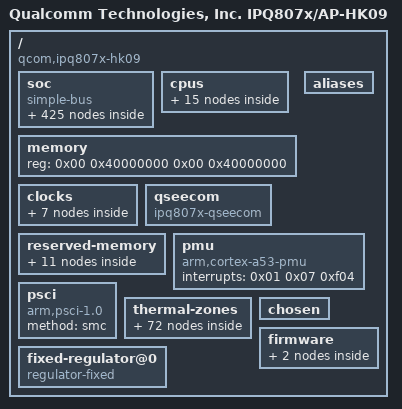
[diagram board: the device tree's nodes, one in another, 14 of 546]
/dts-v1/;

/ {
	qcom,board-id = <0x08 0x00>;
	soc_version_major = <0x2000000>;
	soc_version_minor = <0x00>;
	cpu_type = <0x85010000>;
	flash_type = <0x8000000>;
	boot_version = <0x43524d2d 0x424f4f54 0x2e42462e 0x332e332e 0x312d3030 0x3135360a>;
	#address-cells = <0x02>;
	rpm_version = [43 52 4d 2d 52 50 4d 2e 42 46 2e 32 2e 34 2e 31 2d 30 30 30 38 30 0a];
	tz_version = [43 52 4d 2d 54 5a 2e 42 46 2e 34 2e 30 2e 38 2d 30 30 31 38 39 0a];
	interrupt-parent = <0x01>;
	compatible = "qcom,ipq807x-hk09\0qcom,ipq807x";
	model = "Qualcomm Technologies, Inc. IPQ807x/AP-HK09";
	qcom,pmic-id = <0x00 0x00 0x00 0x00>;
	#size-cells = <0x02>;
	machid = <0x8000108>;
	qcom,msm-id = <0x156 0x00>;

	soc {
		ranges = <0x00 0x00 0x00 0xffffffff>;
		#address-cells = <0x01>;
		compatible = "simple-bus";
		#size-cells = <0x01>;

		ess-switch@3a000000 {
			reset-names = "ppe_rst\0uniphy0_soft_rst\0uniphy0_xpcs_rst\0uniphy1_soft_rst\0uniphy1_xpcs_rst\0uniphy2_soft_rst\0uniphy2_xpcs_rst\0nss_port1_rst\0nss_port2_rst\0nss_port3_rst\0nss_port4_rst\0nss_port5_rst\0nss_port6_rst";
			resets = <0x0b 0x83 0x0b 0x84 0x0b 0x85 0x0b 0x86 0x0b 0x87 0x0b 0x88 0x0b 0x89 0x0b 0x8b 0x0b 0x8c 0x0b 0x8d 0x0b 0x8e 0x0b 0x8f 0x0b 0x90>;
			bm_tick_mode = <0x00>;
			switch_mac_mode = <0x00>;
			switch_inner_bmp = <0x80>;
			switch_mac_mode1 = <0xff>;
			clocks = <0x0b 0xe3 0x0b 0xe4 0x0b 0xb1 0x0b 0xbc 0x0b 0xbd 0x0b 0xc0 0x0b 0xc1 0x0b 0xc4 0x0b 0x92 0x0b 0x93 0x0b 0x94 0x0b 0x95 0x0b 0x96 0x0b 0x97 0x0b 0x86 0x0b 0x85 0x0b 0x8d 0x0b 0x8c 0x0b 0x75 0x0b 0x74 0x0b 0x87 0x0b 0x84 0x0b 0x6d 0x0b 0x77 0x0b 0xd9 0x0b 0x6a 0x0b 0x72 0x0b 0x76 0x0b 0x88 0x0b 0x78 0x0b 0x79 0x0b 0x7a 0x0b 0x7b 0x0b 0x7c 0x0b 0x7d 0x0b 0x7e 0x0b 0x7f 0x0b 0x80 0x0b 0x81 0x0b 0x82 0x0b 0x83 0x0b 0xb2 0x0b 0xb3 0x0b 0xb4 0x0b 0xb5 0x0b 0xb6 0x0b 0xb7 0x0b 0xb8 0x0b 0xb9 0x0b 0xba 0x0b 0xbb 0x0b 0xbe 0x0b 0xbf 0x0b 0xc2 0x0b 0xc3 0x0b 0x0e 0x0b 0x0f>;
			reg = <0x3a000000 0x1000000>;
			switch_access_mode = "local bus";
			switch_mac_mode2 = <0x0d>;
			switch_lan_bmp = <0x3e>;
			switch_wan_bmp = <0x40>;
			compatible = "qcom,ess-switch-ipq807x";
			clock-names = "cmn_ahb_clk\0cmn_sys_clk\0uniphy0_ahb_clk\0uniphy0_sys_clk\0uniphy1_ahb_clk\0uniphy1_sys_clk\0uniphy2_ahb_clk\0uniphy2_sys_clk\0port1_mac_clk\0port2_mac_clk\0port3_mac_clk\0port4_mac_clk\0port5_mac_clk\0port6_mac_clk\0nss_ppe_clk\0nss_ppe_cfg_clk\0nssnoc_ppe_clk\0nssnoc_ppe_cfg_clk\0nss_edma_clk\0nss_edma_cfg_clk\0nss_ppe_ipe_clk\0nss_ppe_btq_clk\0gcc_mdio_ahb_clk\0gcc_nss_noc_clk\0gcc_nssnoc_snoc_clk\0gcc_mem_noc_nss_axi_clk\0gcc_nss_crypto_clk\0gcc_nss_imem_clk\0gcc_nss_ptp_ref_clk\0nss_port1_rx_clk\0nss_port1_tx_clk\0nss_port2_rx_clk\0nss_port2_tx_clk\0nss_port3_rx_clk\0nss_port3_tx_clk\0nss_port4_rx_clk\0nss_port4_tx_clk\0nss_port5_rx_clk\0nss_port5_tx_clk\0nss_port6_rx_clk\0nss_port6_tx_clk\0uniphy0_port1_rx_clk\0uniphy0_port1_tx_clk\0uniphy0_port2_rx_clk\0uniphy0_port2_tx_clk\0uniphy0_port3_rx_clk\0uniphy0_port3_tx_clk\0uniphy0_port4_rx_clk\0uniphy0_port4_tx_clk\0uniphy0_port5_rx_clk\0uniphy0_port5_tx_clk\0uniphy1_port5_rx_clk\0uniphy1_port5_tx_clk\0uniphy2_port6_rx_clk\0uniphy2_port6_tx_clk\0nss_port5_rx_clk_src\0nss_port5_tx_clk_src";
			tm_tick_mode = <0x00>;
			switch_cpu_bmp = <0x01>;

			port_scheduler_resource {

				port@6 {
					l0edrr = <0x80 0x8f>;
					l1cdrr = <0x1c 0x1f>;
					l0sp = <0x38 0x3b>;
					mcast_queue = <0x124 0x127>;
					l0cdrr = <0x80 0x8f>;
					ucast_queue = <0xe0 0xef>;
					l1edrr = <0x1c 0x1f>;
					port_id = <0x06>;
				};

				port@3 {
					l0edrr = <0x50 0x5f>;
					l1cdrr = <0x10 0x13>;
					l0sp = <0x2c 0x2f>;
					mcast_queue = <0x118 0x11b>;
					l0cdrr = <0x50 0x5f>;
					ucast_queue = <0xb0 0xbf>;
					l1edrr = <0x10 0x13>;
					port_id = <0x03>;
				};

				port@0 {
					l0edrr = <0x00 0x2f>;
					l1cdrr = <0x00 0x07>;
					l0sp = <0x00 0x23>;
					mcast_queue = <0x100 0x10f>;
					l0cdrr = <0x00 0x2f>;
					ucast_queue = <0x00 0x8f>;
					l1edrr = <0x00 0x07>;
					port_id = <0x00>;
				};

				port@1 {
					l0edrr = <0x30 0x3f>;
					l1cdrr = <0x08 0x0b>;
					l0sp = <0x24 0x27>;
					mcast_queue = <0x110 0x113>;
					l0cdrr = <0x30 0x3f>;
					ucast_queue = <0x90 0x9f>;
					l1edrr = <0x08 0x0b>;
					port_id = <0x01>;
				};

				port@5 {
					l0edrr = <0x70 0x7f>;
					l1cdrr = <0x18 0x1b>;
					l0sp = <0x34 0x37>;
					mcast_queue = <0x120 0x123>;
					l0cdrr = <0x70 0x7f>;
					ucast_queue = <0xd0 0xdf>;
					l1edrr = <0x18 0x1b>;
					port_id = <0x05>;
				};

				port@4 {
					l0edrr = <0x60 0x6f>;
					l1cdrr = <0x14 0x17>;
					l0sp = <0x30 0x33>;
					mcast_queue = <0x11c 0x11f>;
					l0cdrr = <0x60 0x6f>;
					ucast_queue = <0xc0 0xcf>;
					l1edrr = <0x14 0x17>;
					port_id = <0x04>;
				};

				port@7 {
					l0edrr = <0x90 0x9f>;
					l1cdrr = <0x20 0x23>;
					l0sp = <0x3c 0x3f>;
					mcast_queue = <0x128 0x12b>;
					l0cdrr = <0x90 0x9f>;
					ucast_queue = <0xf0 0xff>;
					l1edrr = <0x20 0x23>;
					port_id = <0x07>;
				};

				port@2 {
					l0edrr = <0x40 0x4f>;
					l1cdrr = <0x0c 0x0f>;
					l0sp = <0x28 0x2b>;
					mcast_queue = <0x114 0x117>;
					l0cdrr = <0x40 0x4f>;
					ucast_queue = <0xa0 0xaf>;
					l1edrr = <0x0c 0x0f>;
					port_id = <0x02>;
				};
			};

			port_scheduler_config {

				port@6 {
					port_id = <0x06>;

					l0scheduler {

						group@0 {
							ucast_loop_pri = <0x10>;
							mcast_queue = <0x124>;
							ucast_queue = <0xe0>;
							cfg = <0x38 0x00 0x80 0x00 0x80>;
							mcast_loop_pri = <0x04>;
						};
					};

					l1scheduler {

						group@1 {
							sp = <0x39>;
							cfg = <0x01 0x1d 0x01 0x1d>;
						};

						group@0 {
							sp = <0x38>;
							cfg = <0x00 0x1c 0x00 0x1c>;
						};
					};
				};

				port@3 {
					port_id = <0x03>;

					l0scheduler {

						group@0 {
							ucast_loop_pri = <0x10>;
							mcast_queue = <0x118>;
							ucast_queue = <0xb0>;
							cfg = <0x2c 0x00 0x50 0x00 0x50>;
							mcast_loop_pri = <0x04>;
						};
					};

					l1scheduler {

						group@1 {
							sp = <0x2d>;
							cfg = <0x01 0x11 0x01 0x11>;
						};

						group@0 {
							sp = <0x2c>;
							cfg = <0x00 0x10 0x00 0x10>;
						};
					};
				};

				port@0 {
					port_id = <0x00>;

					l0scheduler {

						group@3 {
							mcast_queue = <0x103 0x107>;
							ucast_queue = <0x03 0x07 0x0b>;
							cfg = <0x00 0x03 0x03 0x03 0x03>;
						};

						group@1 {
							mcast_queue = <0x101 0x105>;
							ucast_queue = <0x01 0x05 0x09>;
							cfg = <0x00 0x01 0x01 0x01 0x01>;
						};

						group@2 {
							mcast_queue = <0x102 0x106>;
							ucast_queue = <0x02 0x06 0x0a>;
							cfg = <0x00 0x02 0x02 0x02 0x02>;
						};

						group@0 {
							mcast_queue = <0x100 0x104>;
							ucast_queue = <0x00 0x04 0x08>;
							cfg = <0x00 0x00 0x00 0x00 0x00>;
						};
					};

					l1scheduler {

						group@0 {
							sp = <0x00 0x01>;
							cfg = <0x00 0x00 0x00 0x00>;
						};
					};
				};

				port@1 {
					port_id = <0x01>;

					l0scheduler {

						group@0 {
							ucast_loop_pri = <0x10>;
							mcast_queue = <0x110>;
							ucast_queue = <0x90>;
							cfg = <0x24 0x00 0x30 0x00 0x30>;
							mcast_loop_pri = <0x04>;
						};
					};

					l1scheduler {

						group@1 {
							sp = <0x25>;
							cfg = <0x01 0x09 0x01 0x09>;
						};

						group@0 {
							sp = <0x24>;
							cfg = <0x00 0x08 0x00 0x08>;
						};
					};
				};

				port@5 {
					port_id = <0x05>;

					l0scheduler {

						group@0 {
							ucast_loop_pri = <0x10>;
							mcast_queue = <0x120>;
							ucast_queue = <0xd0>;
							cfg = <0x34 0x00 0x70 0x00 0x70>;
							mcast_loop_pri = <0x04>;
						};
					};

					l1scheduler {

						group@1 {
							sp = <0x35>;
							cfg = <0x01 0x19 0x01 0x19>;
						};

						group@0 {
							sp = <0x34>;
							cfg = <0x00 0x18 0x00 0x18>;
						};
					};
				};

				port@4 {
					port_id = <0x04>;

					l0scheduler {

						group@0 {
							ucast_loop_pri = <0x10>;
							mcast_queue = <0x11c>;
							ucast_queue = <0xc0>;
							cfg = <0x30 0x00 0x60 0x00 0x60>;
							mcast_loop_pri = <0x04>;
						};
					};

					l1scheduler {

						group@1 {
							sp = <0x31>;
							cfg = <0x01 0x15 0x01 0x15>;
						};

						group@0 {
							sp = <0x30>;
							cfg = <0x00 0x14 0x00 0x14>;
						};
					};
				};

				port@7 {
					port_id = <0x07>;

					l0scheduler {

						group@0 {
							ucast_loop_pri = <0x10>;
							mcast_queue = <0x128>;
							ucast_queue = <0xf0>;
							cfg = <0x3c 0x00 0x90 0x00 0x90>;
						};
					};

					l1scheduler {

						group@1 {
							sp = <0x3d>;
							cfg = <0x01 0x21 0x01 0x21>;
						};

						group@0 {
							sp = <0x3c>;
							cfg = <0x00 0x20 0x00 0x20>;
						};
					};
				};

				port@2 {
					port_id = <0x02>;

					l0scheduler {

						group@0 {
							ucast_loop_pri = <0x10>;
							mcast_queue = <0x114>;
							ucast_queue = <0xa0>;
							cfg = <0x28 0x00 0x40 0x00 0x40>;
							mcast_loop_pri = <0x04>;
						};
					};

					l1scheduler {

						group@1 {
							sp = <0x29>;
							cfg = <0x01 0x0d 0x01 0x0d>;
						};

						group@0 {
							sp = <0x28>;
							cfg = <0x00 0x0c 0x00 0x0c>;
						};
					};
				};
			};
		};

		syscon@1100000 {
			phandle = <0x17>;
			reg = <0x1100000 0xafff>;
			compatible = "syscon";
			linux,phandle = <0x17>;
		};

		usb3@8A00000 {
			clocks = <0x0b 0xe5 0x0b 0xe6 0x0b 0xc6 0x0b 0xca 0x0b 0xc7 0x0b 0xc8 0x0b 0xc5 0x0b 0xc9>;
			ranges;
			#address-cells = <0x01>;
			assigned-clock-rates = <0x7f27450 0x7f27450 0x1312d00>;
			reg = <0x8af8800 0x100 0x8a00000 0xcd00>;
			status = "ok";
			reg-names = "qscratch_base\0dwc3_base";
			qca,host = <0x01>;
			compatible = "qcom,dwc3";
			clock-names = "snoc_bus_timeout2\0sys_noc_axi\0master\0sleep\0mock_utmi\0cfg_ahb_clk\0aux_clk\0pipe_clk";
			assigned-clocks = <0x0b 0xe6 0x0b 0xc6 0x0b 0xc7>;
			#size-cells = <0x01>;
			qcom,usb-dbm = <0x25>;

			dwc3@8A00000 {
				snps,dis_u2_susphy_quirk;
				dr_mode = "host";
				snps,nominal-elastic-buffer;
				snps,dis_ep_cache_eviction;
				snps,is-utmi-l1-suspend;
				usb-phy = <0x26 0x27>;
				snps,hird-threshold = [00];
				snps,dis_u3_susphy_quirk;
				snps,quirk-ref-clock-period = <0x32>;
				reg = <0x8a00000 0xcd00>;
				tx-fifo-resize;
				interrupts = <0x00 0x8c 0x00>;
				compatible = "snps,dwc3";
				qcom,emulation = <0x01>;
				usb2-susphy-quirk;
				snps,usb3-u1u2-disable;
			};
		};

		dbm@0x8AF8000 {
			qcom,reset-ep-after-lpm-resume;
			phandle = <0x25>;
			reg = <0x8af8000 0x300>;
			compatible = "qcom,usb-dbm-1p5";
			linux,phandle = <0x25>;
		};

		dbgui@6108000 {
			clocks = <0x0b 0xee 0x0b 0xed>;
			reg = <0x6108000 0x1000>;
			qcom,dbgui-addr-offset = <0x30>;
			qcom,dbgui-size = <0x40>;
			reg-names = "dbgui-base";
			coresight-name = "coresight-dbgui";
			compatible = "qcom,coresight-dbgui";
			qcom,dbgui-data-offset = <0x130>;
			clock-names = "core_clk\0core_a_clk";

			port {

				endpoint {
					phandle = <0x43>;
					remote-endpoint = <0x56>;
					linux,phandle = <0x43>;
				};
			};
		};

		clock-controller@b188000 {
			phandle = <0x03>;
			reg = <0xb188000 0x1000>;
			compatible = "qcom,arm-cortex-acc";
			linux,phandle = <0x03>;
		};

		cti@619b000 {
			cpu = <0x52>;
			clocks = <0x0b 0xee 0x0b 0xed>;
			reg = <0x619b000 0x1000>;
			reg-names = "cti-base";
			coresight-name = "coresight-cti-cpu3";
			compatible = "arm,coresight-cti";
			clock-names = "core_clk\0core_a_clk";
		};

		replicator@6026000 {
			clocks = <0x0b 0xee 0x0b 0xed>;
			reg = <0x6026000 0x1000>;
			reg-names = "replicator-base";
			coresight-name = "coresight-replicator";
			compatible = "arm,primecell";
			clock-names = "apb_pclk\0core_a_clk";
			arm,primecell-periphid = <0x3b909>;

			ports {
				#address-cells = <0x01>;
				#size-cells = <0x00>;

				port@0 {
					reg = <0x00>;

					endpoint {
						phandle = <0x36>;
						remote-endpoint = <0x37>;
						linux,phandle = <0x36>;
					};
				};

				port@1 {
					reg = <0x00>;

					endpoint {
						phandle = <0x39>;
						slave-mode;
						remote-endpoint = <0x38>;
						linux,phandle = <0x39>;
					};
				};
			};
		};

		wifi2@f00000 {
			mhi,max-channels = <0x1e>;
			qcom,wlan-ramdump-dynamic = <0x400000>;
			status = "disabled";
			mhi,timeout = <0x2710>;
			qrtr_node_id = <0x20>;
			compatible = "qcom,cnss-qcn9000";
			qca,auto-restart;
		};

		ledc@191E000 {
			qcom,ledc_blink_indices = <0x05 0x06 0x07 0x0e 0x0d 0x01 0x09 0x0a 0x02 0x0b 0x0c 0x03 0x04>;
			qcom,tcsr_ledc_values = <0x320193 0x00 0x00 0x00 0x00 0xffffffff 0x00 0xffffffff 0x7d0820 0x00 0x10482094 0x3ffffe1>;
			reg = <0x191e000 0x20070>;
			qcom,ledc_blink_indices_cnt = <0x0d>;
			status = "disabled";
			reg-names = "ledc_base_addr";
			qcom,ledc_blink_idx_src_pair = <0x03 0x14 0x04 0x15 0x05 0x16>;
			compatible = "qca,ledc";
		};

		dcc@b3000 {
			clocks = <0x0b 0xf3>;
			reg = <0xb3000 0x1000 0xb4000 0x800 0x4a2000 0x08>;
			status = "ok";
			reg-names = "dcc-base\0dcc-ram-base\0gcnt_lo_hi";
			qca,save-reg;
			compatible = "qca,dcc";
			no_xpu_support;
			clock-names = "dcc_clk";
		};

		nss@40000000 {
			qcom,pptp-enabled;
			qcom,vxlan-enabled;
			qcom,igs-enabled;
			qcom,match-enabled;
			qcom,ppe-enabled;
			qcom,num-irq = <0x0a>;
			qcom,tunipip6-enabled;
			qcom,gre-enabled;
			qcom,mirror-enabled;
			qcom,ipv4-reasm-enabled;
			qcom,map-t-enabled;
			qcom,portid-enabled;
			qcom,num-queue = <0x04>;
			qcom,ipv6-reasm-enabled;
			qcom,pppoe-enabled;
			clocks = <0x0b 0x77 0x0b 0x88 0x0b 0x73 0x0b 0x71 0x0b 0x76 0x0b 0x8e 0x0b 0x6a 0x0b 0xd9 0x0b 0x8f 0x0b 0x70 0x0b 0x6f 0x0b 0x8a 0x0b 0x89 0x0b 0x90 0x0b 0x9a 0x0b 0x98 0x0b 0x99 0x0b 0x9b 0x0b 0xda>;
			qcom,gre-redir-mark-enabled;
			qcom,low-frequency = <0x2ca1c800>;
			qcom,mid-frequency = <0x59439000>;
			reg = <0x39000000 0x1000 0x38000000 0x30000 0xb111000 0x1000>;
			qcom,num-pri = <0x04>;
			qcom,gre-redir-enabled;
			qcom,ipv6-enabled;
			qcom,wlanredirect-enabled;
			qcom,l2tpv2-enabled;
			reg-names = "nphys\0vphys\0qgic-phys";
			qcom,load-addr = <0x40000000>;
			qcom,bridge-enabled;
			interrupts = <0x00 0x179 0x01 0x00 0x17a 0x01 0x00 0x17b 0x01 0x00 0x17c 0x01 0x00 0x17d 0x01 0x00 0x17e 0x01 0x00 0x17f 0x01 0x00 0x180 0x01 0x00 0x181 0x01 0x00 0x182 0x01>;
			compatible = "qcom,nss";
			mx-supply = <0x21>;
			clock-names = "nss-noc-clk\0nss-ptp-ref-clk\0nss-csr-clk\0nss-cfg-clk\0nss-imem-clk\0nss-nssnoc-qosgen-ref-clk\0nss-mem-noc-nss-axi-clk\0nss-nssnoc-snoc-clk\0nss-nssnoc-timeout-ref-clk\0nss-ce-axi-clk\0nss-ce-apb-clk\0nss-nssnoc-ce-axi-clk\0nss-nssnoc-ce-apb-clk\0nss-nssnoc-ahb-clk\0nss-core-clk\0nss-ahb-clk\0nss-axi-clk\0nss-mpt-clk\0nss-nc-axi-clk";
			qcom,shaping-enabled;
			qcom,tun6rd-enabled;
			qcom,id = <0x00>;
			npu-supply = <0x20>;
			qcom,vlan-enabled;
			qcom,wlan-dataplane-offload-enabled;
			qcom,ipv4-enabled;
			qcom,max-frequency = <0x64b54000>;
		};

		cti@6018000 {
			phandle = <0x35>;
			clocks = <0x0b 0xee 0x0b 0xed>;
			reg = <0x6018000 0x1000>;
			reg-names = "cti-base";
			coresight-name = "coresight-cti8";
			compatible = "arm,coresight-cti";
			clock-names = "core_clk\0core_a_clk";
			linux,phandle = <0x35>;
		};

		qcom,test@0 {
			status = "disabled";
			compatible = "qcom,testmhi";
		};

		ssphy@78000 {
			reset-names = "usb3_phy_reset\0usb3phy_phy_reset";
			resets = <0x0b 0x29 0x0b 0x2a>;
			qcom,qmp-phy-reg-offset = <0x988 0x98c 0x990 0x994 0x974 0x8d8 0x8dc 0x804 0x800 0x808>;
			phandle = <0x27>;
			clocks = <0x0b 0xc5 0x0b 0xc9>;
			reg = <0x78000 0x45c 0x193f244 0x04 0x8af8800 0x100 0x7e000 0x18>;
			qcom,qmp-phy-init-seq = <0xac 0x14 0x1a 0x00 0x34 0x08 0x08 0x00 0x174 0x30 0x30 0x00 0x3c 0x06 0x06 0x00 0xb4 0x00 0x00 0x00 0xb8 0x08 0x08 0x00 0x194 0x06 0x06 0x3e8 0x19c 0x01 0x01 0x00 0x178 0x00 0x00 0x00 0xd0 0x82 0x82 0x00 0xdc 0x55 0x55 0x00 0xe0 0x55 0x55 0x00 0xe4 0x03 0x03 0x00 0x78 0x0b 0x0b 0x00 0x84 0x16 0x16 0x00 0x90 0x28 0x28 0x00 0x108 0x80 0x80 0x00 0x10c 0x00 0x00 0x00 0x184 0x0a 0x0a 0x00 0x4c 0x15 0x15 0x00 0x50 0x34 0x34 0x00 0x54 0x00 0x00 0x00 0xc8 0x00 0x00 0x00 0x18c 0x00 0x00 0x00 0xcc 0x00 0x00 0x00 0x128 0x00 0x00 0x00 0x0c 0x0a 0x0a 0x00 0x10 0x01 0x01 0x00 0x1c 0x31 0x31 0x00 0x20 0x01 0x01 0x00 0x14 0x00 0x00 0x00 0x18 0x00 0x00 0x00 0x24 0xde 0xde 0x00 0x28 0x07 0x07 0x00 0x48 0x0f 0x0f 0x00 0x70 0x0f 0x0f 0x00 0x100 0x80 0x80 0x00 0x440 0x0b 0x0b 0x00 0x4d8 0x02 0x02 0x00 0x4dc 0x6c 0x6c 0x00 0x4e0 0xbb 0xb8 0x00 0x508 0x77 0x77 0x00 0x50c 0x80 0x80 0x00 0x514 0x03 0x03 0x00 0x51c 0x16 0x16 0x00 0x448 0x75 0x75 0x00 0x454 0x00 0x00 0x00 0x40c 0x0a 0x0a 0x00 0x41c 0x06 0x06 0x00 0x510 0x00 0x00 0x00 0x268 0x45 0x45 0x00 0x2ac 0x12 0x12 0x00 0x294 0x06 0x06 0x00 0x254 0x00 0x00 0x00 0x8c8 0x83 0x83 0x00 0x8c4 0x02 0x02 0x00 0x8cc 0x09 0x09 0x00 0x8d0 0xa2 0xa2 0x00 0x8d4 0x85 0x85 0x00 0x880 0xd1 0xd1 0x00 0x884 0x1f 0x1f 0x00 0x888 0x47 0x47 0x00 0x80c 0x9f 0x9f 0x00 0x824 0x17 0x17 0x00 0x828 0x0f 0x0f 0x00 0x8b8 0x75 0x75 0x00 0x8bc 0x13 0x13 0x00 0x8b0 0x86 0x86 0x00 0x8a0 0x04 0x04 0x00 0x88c 0x44 0x44 0x00 0x870 0xe7 0xe7 0x00 0x874 0x03 0x03 0x00 0x878 0x40 0x40 0x00 0x87c 0x00 0x00 0x00 0x9d8 0x88 0x88 0x00 0xffffffff 0xffffffff 0x00 0x00>;
			status = "ok";
			reg-names = "qmp_phy_base\0vls_clamp_reg\0qscratch_base\0ahb2phy_base";
			compatible = "qcom,usb-ssphy-qmp";
			clock-names = "aux_clk\0pipe_clk";
			linux,phandle = <0x27>;
		};

		dp4 {
			qcom,link-poll = <0x01>;
			qcom,mactype = <0x00>;
			local-mac-address = [00 00 00 00 00 00];
			phy-mode = "sgmii";
			reg = <0x3a001600 0x200>;
			device_type = "network";
			compatible = "qcom,nss-dp";
			qcom,id = <0x04>;
			qcom,phy-mdio-addr = <0x03>;
		};

		csr@6001000 {
			clocks = <0x0b 0xee 0x0b 0xed>;
			qcom,blk-size = <0x01>;
			reg = <0x6001000 0x1000>;
			reg-names = "csr-base";
			coresight-name = "coresight-csr";
			compatible = "qcom,coresight-csr";
			clock-names = "core_clk\0core_a_clk";
		};

		sdcc1ice@7803000 {
			phandle = <0x16>;
			qcom,msm-bus,vectors-KBps = <0x4e 0x200 0x00 0x00 0x4e 0x200 0x3e8 0x00>;
			reg = <0x7803000 0x2000>;
			qcom,bus-vector-names = "MIN\0MAX";
			interrupts = <0x00 0x138 0x00>;
			qcom,instance-type = "sdcc";
			compatible = "qcom,ice";
			linux,phandle = <0x16>;
		};

		qcom,spmi@200f000 {
			qcom,ee = <0x00>;
			#address-cells = <0x02>;
			reg = <0x200f000 0x1000 0x2400000 0x800000 0x2c00000 0x800000 0x3800000 0x200000 0x200a000 0x700>;
			#interrupt-cells = <0x04>;
			interrupt-controller;
			reg-names = "core\0chnls\0obsrvr\0intr\0cnfg";
			interrupt-names = "periph_irq";
			qcom,channel = <0x00>;
			interrupts = <0x00 0xbe 0x00>;
			compatible = "qcom,spmi-pmic-arb";
			#size-cells = <0x00>;
			cell-index = <0x00>;

			pmic@0 {
				#address-cells = <0x01>;
				reg = <0x00 0x00>;
				compatible = "qcom,spmi-pmic";
				#size-cells = <0x00>;

				vadc@3100 {
					#address-cells = <0x01>;
					reg = <0x3100 0x100>;
					interrupts = <0x00 0x31 0x00 0x01>;
					compatible = "qcom,pmp8074-spmi-vadc";
					#io-channel-cells = <0x01>;
					#size-cells = <0x00>;

					die_temp {
						reg = <0x06>;
					};

					pa_therm3 {
						qcom,vadc-thermal-node;
						reg = <0x0f>;
					};

					pa_therm1 {
						qcom,vadc-thermal-node;
						reg = <0x0d>;
					};

					pa_therm2 {
						qcom,vadc-thermal-node;
						reg = <0x0e>;
					};
				};
			};

			pmic@1 {
				#address-cells = <0x01>;
				reg = <0x01 0x00>;
				compatible = "qcom,spmi-pmic";
				#size-cells = <0x00>;

				regulators {
					vdd_ldo11-supply = <0x32>;
					vdd_s4-supply = <0x32>;
					vdd_s3-supply = <0x32>;
					compatible = "qcom,pmd9655-regulators";

					ldo11 {
						regulator-min-microvolt = <0x10d880>;
						regulator-name = "pmd9655_ldo11";
						regulator-max-microvolt = <0x325aa0>;
					};

					s3 {
						regulator-always-on;
						phandle = <0x5b>;
						regulator-boot-on;
						regulator-min-microvolt = <0x90880>;
						regulator-name = "pmd9655_s3";
						regulator-max-microvolt = <0x103c40>;
						linux,phandle = <0x5b>;
					};

					s4 {
						regulator-always-on;
						phandle = <0x5c>;
						regulator-boot-on;
						regulator-min-microvolt = <0xadd40>;
						regulator-name = "pmd9655_s4";
						regulator-max-microvolt = <0xf2300>;
						linux,phandle = <0x5c>;
					};
				};
			};
		};

		cti@6016000 {
			clocks = <0x0b 0xee 0x0b 0xed>;
			reg = <0x6016000 0x1000>;
			reg-names = "cti-base";
			coresight-name = "coresight-cti6";
			compatible = "arm,coresight-cti";
			clock-names = "core_clk\0core_a_clk";
		};

		funnel@6100000 {
			clocks = <0x0b 0xee 0x0b 0xed>;
			reg = <0x6100000 0x1000>;
			reg-names = "funnel-base";
			coresight-name = "coresight-funnel-center";
			compatible = "arm,primecell";
			clock-names = "apb_pclk\0core_a_clk";
			arm,primecell-periphid = <0x3b908>;

			ports {
				#address-cells = <0x01>;
				#size-cells = <0x00>;

				port@0 {
					reg = <0x00>;

					endpoint {
						phandle = <0x3c>;
						remote-endpoint = <0x42>;
						linux,phandle = <0x3c>;
					};
				};

				port@1 {
					reg = <0x02>;

					endpoint {
						phandle = <0x56>;
						slave-mode;
						remote-endpoint = <0x43>;
						linux,phandle = <0x56>;
					};
				};
			};
		};

		qusb@59000 {
			reset-names = "usb2_phy_reset";
			resets = <0x0b 0x30>;
			phandle = <0x28>;
			phy_type = "utmi";
			reg = <0x59000 0x180 0x8cf8800 0x400 0x1841030 0x04>;
			status = "ok";
			reg-names = "qusb_phy_base\0qscratch_base\0ref_clk_addr";
			qcom,qusb-phy-init-seq = <0xf8 0x80 0x83 0x84 0x83 0x88 0xc0 0x8c 0x30 0x08 0x79 0x0c 0x21 0x10 0x14 0x9c 0x80 0x04 0x9f 0x1c>;
			compatible = "qcom,qusb2phy";
			linux,phandle = <0x28>;
		};

		phy@84000 {
			reset-names = "phy\0phy_phy";
			resets = <0x0b 0x4e 0x0b 0x4f>;
			phandle = <0x2b>;
			clocks = <0x0b 0xa4>;
			reg = <0x84000 0x1000>;
			#phy-cells = <0x00>;
			compatible = "qca,pcie-qmp-phy-gen3";
			clock-names = "pipe_clk";
			linux,phandle = <0x2b>;
		};

		pci@10000000 {
			linux,pci-domain = <0x01>;
			reset-names = "pipe\0sleep\0sticky\0axi_m\0axi_s\0ahb\0axi_m_sticky";
			resets = <0x0b 0x7c 0x0b 0x7d 0x0b 0x7e 0x0b 0x7f 0x0b 0x80 0x0b 0x81 0x0b 0x82>;
			clocks = <0x0b 0xea 0x0b 0xa7 0x0b 0xa8 0x0b 0xa5 0x0b 0xa6>;
			phy-names = "pciephy";
			perst-gpio = <0x1d 0x3d 0x01>;
			ranges = <0x81000000 0x00 0x10200000 0x10200000 0x00 0x10000 0x82000000 0x00 0x10220000 0x10220000 0x00 0xfde0000>;
			#address-cells = <0x03>;
			reg = <0x10000000 0xf1d 0x10000f20 0xa8 0x88000 0x2000 0x10100000 0x1000>;
			status = "disabled";
			#interrupt-cells = <0x01>;
			bus-range = <0x00 0xff>;
			interrupt-map = <0x00 0x00 0x00 0x01 0x01 0x00 0x8e 0x04 0x00 0x00 0x00 0x02 0x01 0x00 0x8f 0x04 0x00 0x00 0x00 0x03 0x01 0x00 0x90 0x04 0x00 0x00 0x00 0x04 0x01 0x00 0x91 0x04>;
			reg-names = "dbi\0elbi\0parf\0config";
			interrupt-names = "msi\0msi_0\0msi_1\0msi_2\0msi_3\0msi_4\0msi_5\0msi_6\0msi_7\0msi_8\0msi_9\0msi_10\0msi_11\0msi_12\0msi_13\0msi_14\0msi_15";
			num-lanes = <0x01>;
			device_type = "pci";
			interrupts = <0x00 0x55 0x00 0x00 0x1b0 0x00 0x00 0x1b1 0x00 0x00 0x1b2 0x00 0x00 0x1b3 0x00 0x00 0x1b4 0x00 0x00 0x1b5 0x00 0x00 0x1b6 0x00 0x00 0x1b7 0x00 0x00 0x1b8 0x00 0x00 0x1b9 0x00 0x00 0x1ba 0x00 0x00 0x1bb 0x00 0x00 0x1bc 0x00 0x00 0x1bd 0x00 0x00 0x1be 0x00 0x00 0x1bf 0x00>;
			phys = <0x30>;
			compatible = "qcom,pcie-ipq807x";
			clock-names = "sys_noc\0axi_m\0axi_s\0ahb\0aux";
			interrupt-map-mask = <0x00 0x00 0x00 0x07>;
			qcom,msi-gicm-base = <0x1d0>;
			#size-cells = <0x02>;
			qcom,msi-gicm-addr = <0xb00a040>;

			pcie1_rp {
				reg = <0x00 0x00 0x00 0x00 0x00>;
			};
		};

		cti@6015000 {
			clocks = <0x0b 0xee 0x0b 0xed>;
			reg = <0x6015000 0x1000>;
			reg-names = "cti-base";
			coresight-name = "coresight-cti5";
			compatible = "arm,coresight-cti";
			clock-names = "core_clk\0core_a_clk";
		};

		q6v5_wcss@CD00000 {
			phandle = <0x15>;
			interrupts-extended = <0x01 0x00 0x145 0x01 0x12 0x00 0x00 0x12 0x01 0x00 0x12 0x03 0x00>;
			qca,extended-intc;
			reg = <0xcd00000 0x4040 0x194f000 0x10 0x1952000 0x10 0x4ab000 0x20 0x1818000 0x110 0x1859000 0x10 0x1945000 0x10>;
			qcom,smem-states = <0x13 0x00 0x13 0x01>;
			reg-names = "wcss-base\0tcsr-q6-base\0tcsr-base\0mpm-base\0gcc-wcss-bcr-base\0gcc-wcss-misc-base\0tcsr-global";
			memory-region = <0x10 0x11>;
			interrupt-names = "wdog\0qcom,gpio-err-fatal\0qcom,gpio-err-ready\0qcom,gpio-stop-ack";
			compatible = "qca,q6v5-wcss-rproc-ipq807x";
			qca,auto-restart;
			qca,secure;
			qca,dump-q6-reg;
			qcom,smem-state-names = "shutdown\0stop";
			linux,phandle = <0x15>;
			firmware = "IPQ8074/q6_fw.mdt";
		};

		dp3 {
			qcom,link-poll = <0x01>;
			qcom,mactype = <0x00>;
			local-mac-address = [00 00 00 00 00 00];
			phy-mode = "sgmii";
			reg = <0x3a001400 0x200>;
			device_type = "network";
			compatible = "qcom,nss-dp";
			qcom,id = <0x03>;
			qcom,phy-mdio-addr = <0x02>;
		};

		syscon@1905000 {
			phandle = <0x1b>;
			reg = <0x1905000 0x8000>;
			compatible = "syscon";
			linux,phandle = <0x1b>;
		};

		cti@601b000 {
			clocks = <0x0b 0xee 0x0b 0xed>;
			reg = <0x601b000 0x1000>;
			reg-names = "cti-base";
			coresight-name = "coresight-cti11";
			compatible = "arm,coresight-cti";
			clock-names = "core_clk\0core_a_clk";
		};

		cti@6014000 {
			clocks = <0x0b 0xee 0x0b 0xed>;
			reg = <0x6014000 0x1000>;
			reg-names = "cti-base";
			coresight-name = "coresight-cti4";
			compatible = "arm,coresight-cti";
			clock-names = "core_clk\0core_a_clk";
		};

		syscon@1945000 {
			phandle = <0x1e>;
			reg = <0x1945000 0xe000>;
			compatible = "syscon";
			linux,phandle = <0x1e>;
		};

		cti@619a000 {
			cpu = <0x50>;
			clocks = <0x0b 0xee 0x0b 0xed>;
			reg = <0x619a000 0x1000>;
			reg-names = "cti-base";
			coresight-name = "coresight-cti-cpu2";
			compatible = "arm,coresight-cti";
			clock-names = "core_clk\0core_a_clk";
		};

		i2c@78b6000 {
			dma-names = "rx\0tx";
			clocks = <0x0b 0x54 0x0b 0x57>;
			#address-cells = <0x01>;
			dmas = <0x0e 0x0f 0x0e 0x0e>;
			reg = <0x78b6000 0x600>;
			status = "disabled";
			interrupts = <0x00 0x60 0x04>;
			compatible = "qcom,i2c-qup-v2.2.1";
			clock-names = "iface\0core";
			#size-cells = <0x00>;
			clock-frequency = <0x61a80>;
		};

		cti@610c000 {
			clocks = <0x0b 0xee 0x0b 0xed>;
			reg = <0x610c000 0x1000>;
			reg-names = "cti-base";
			coresight-name = "coresight-cti-rpm-cpu0";
			compatible = "arm,coresight-cti";
			clock-names = "core_clk\0core_a_clk";
		};

		stm@6002000 {
			clocks = <0x0b 0xee 0x0b 0xed>;
			reg = <0x6002000 0x1000 0x9280000 0x180000>;
			reg-names = "stm-base\0stm-data-base";
			coresight-name = "coresight-stm";
			compatible = "arm,primecell";
			clock-names = "apb_pclk\0core_a_clk";
			arm,primecell-periphid = <0x3b962>;

			port {

				endpoint {
					phandle = <0x40>;
					remote-endpoint = <0x55>;
					linux,phandle = <0x40>;
				};
			};
		};

		ess-uniphy@7a00000 {
			reg = <0x7a00000 0x30000>;
			uniphy_access_mode = "local bus";
			compatible = "qcom,ess-uniphy";
		};

		dma@704000 {
			qcom,controlled-remotely = <0x01>;
			phandle = <0x23>;
			clocks = <0x0b 0x67>;
			qcom,ee = <0x01>;
			reg = <0x704000 0x20000>;
			#dma-cells = <0x01>;
			status = "ok";
			interrupts = <0x00 0xcf 0x00>;
			compatible = "qcom,bam-v1.7.0";
			clock-names = "bam_clk";
			linux,phandle = <0x23>;
		};

		qcom_mdss_qpic@7980000 {
			dma-names = "chan";
			clocks = <0x0b 0xac 0x0b 0xab>;
			dmas = <0x24 0x06>;
			reg = <0x7980000 0x24000>;
			status = "disabled";
			interrupts = <0x00 0x97 0x00>;
			compatible = "qcom,mdss_qpic";
			clock-names = "core\0aon";
		};

		usb3@8C00000 {
			clocks = <0x0b 0xe7 0x0b 0xe8 0x0b 0xcc 0x0b 0xd0 0x0b 0xcd 0x0b 0xce 0x0b 0xcb 0x0b 0xcf>;
			ranges;
			#address-cells = <0x01>;
			assigned-clock-rates = <0x7f27450 0x7f27450 0x1312d00>;
			reg = <0x8cf8800 0x100 0x8c00000 0xcd00>;
			status = "ok";
			reg-names = "qscratch_base\0dwc3_base";
			qca,host = <0x01>;
			compatible = "qcom,dwc3";
			clock-names = "snoc_bus_timeout3\0sys_noc_axi\0master\0sleep\0mock_utmi\0cfg_ahb_clk\0aux_clk\0pipe_clk";
			assigned-clocks = <0x0b 0xe8 0x0b 0xcc 0x0b 0xcd>;
			#size-cells = <0x01>;

			dwc3@8C00000 {
				snps,dis_u2_susphy_quirk;
				dr_mode = "host";
				snps,nominal-elastic-buffer;
				snps,dis_ep_cache_eviction;
				snps,is-utmi-l1-suspend;
				usb-phy = <0x28 0x29>;
				snps,hird-threshold = [00];
				snps,dis_u3_susphy_quirk;
				snps,quirk-ref-clock-period = <0x32>;
				reg = <0x8c00000 0xcd00>;
				tx-fifo-resize;
				interrupts = <0x00 0x63 0x00>;
				compatible = "snps,dwc3";
				qcom,emulation = <0x01>;
				usb2-susphy-quirk;
				snps,usb3-u1u2-disable;
			};
		};

		funnel@6120000 {
			clocks = <0x0b 0xee 0x0b 0xed>;
			reg = <0x6120000 0x1000>;
			reg-names = "funnel-base";
			coresight-name = "coresight-funnel-right";
			compatible = "arm,primecell";
			clock-names = "apb_pclk\0core_a_clk";
			arm,primecell-periphid = <0x3b908>;

			ports {
				#address-cells = <0x01>;
				#size-cells = <0x00>;

				port@0 {
					reg = <0x00>;

					endpoint {
						phandle = <0x3d>;
						remote-endpoint = <0x44>;
						linux,phandle = <0x3d>;
					};
				};

				port@1 {
					reg = <0x03>;

					endpoint {
						phandle = <0x47>;
						slave-mode;
						remote-endpoint = <0x45>;
						linux,phandle = <0x47>;
					};
				};
			};
		};

		wifi_platdata {
			status = "ok";
			compatible = "wifi,wifi-platdata";
			wifi,power5v_pa_en_gpio = <0x1d 0x00 0x01>;
		};

		qcom_q6v5_wcss@CD00000 {
			m3_firmware = "IPQ8074/m3_fw.mdt";
			reset-names = "wcss_aon_reset\0wcss_reset\0wcss_q6_reset";
			resets = <0x0b 0x59 0x0b 0x16 0x0b 0x17>;
			phandle = <0x31>;
			interrupts-extended = <0x01 0x00 0x145 0x01 0x12 0x00 0x00 0x12 0x01 0x00 0x12 0x02 0x00 0x12 0x03 0x00>;
			qcom,halt-regs = <0x1e 0xa000 0xd000 0x00>;
			qca,extended-intc;
			reg = <0xcd00000 0x4040 0x4ab000 0x20>;
			qcom,smem-states = <0x13 0x00 0x13 0x01>;
			reg-names = "qdsp6\0rmb";
			memory-region = <0x10 0x11>;
			interrupt-names = "wdog\0fatal\0ready\0handover\0stop-ack";
			compatible = "qcom,ipq8074-wcss-pil";
			qca,auto-restart;
			qcom,smem-state-names = "shutdown\0stop";
			linux,phandle = <0x31>;
			firmware = "IPQ8074/q6_fw.mdt";

			glink-edge {
				global_timer = "\0JP";
				mboxes = <0x1f 0x08>;
				interrupts = <0x00 0x141 0x01>;
				qcom,remote-pid = <0x01>;

				rpm_requests {
					qcom,glink-channels = "IPCRTR";
				};
			};
		};

		cti@601a000 {
			clocks = <0x0b 0xee 0x0b 0xed>;
			reg = <0x601a000 0x1000>;
			reg-names = "cti-base";
			coresight-name = "coresight-cti10";
			compatible = "arm,coresight-cti";
			clock-names = "core_clk\0core_a_clk";
		};

		spi@78b8000 {
			dma-names = "tx\0rx";
			clocks = <0x0b 0x5c 0x0b 0x54>;
			#address-cells = <0x01>;
			dmas = <0x0e 0x12 0x0e 0x13>;
			reg = <0x78b8000 0x600>;
			status = "disabled";
			interrupts = <0x00 0x62 0x00>;
			spi-max-frequency = <0x2faf080>;
			compatible = "qcom,spi-qup-v2.2.1";
			clock-names = "core\0iface";
			#size-cells = <0x00>;
		};

		cti@6011000 {
			clocks = <0x0b 0xee 0x0b 0xed>;
			reg = <0x6011000 0x1000>;
			reg-names = "cti-base";
			coresight-name = "coresight-cti1";
			compatible = "arm,coresight-cti";
			clock-names = "core_clk\0core_a_clk";
		};

		sdhci@7864900 {
			qcom,vdd-io-voltage-level = <0x1b7740 0x2d0370>;
			qcom,bus-width = <0x04>;
			qcom,vdd-io-lpm-sup;
			qcom,msm-bus,vectors-KBps = <0x51 0x200 0x00 0x00 0x51 0x200 0x416 0xc80 0x51 0x200 0xcc3e 0x27100 0x51 0x200 0xff50 0x30d40 0x51 0x200 0x1fe9e 0x61a80 0x51 0x200 0x3fd3e 0xc3500 0x51 0x200 0x3fd3e 0xc3500 0x51 0x200 0x146cc2 0x3e8000>;
			clocks = <0x0b 0xaf 0x0b 0xb0>;
			qcom,vdd-voltage-level = <0x2d0370 0x2d0370>;
			qcom,msm-bus,num-cases = <0x08>;
			reg = <0x7864900 0x500 0x7864000 0x800>;
			qcom,large-address-bus;
			status = "disabled";
			qcom,vdd-io-always-on;
			qcom,vdd-io-current-level = <0xc8 0x55f0>;
			reg-names = "hc_mem\0core_mem";
			qcom,msm-bus,num-paths = <0x01>;
			qcom,max_clk = <0xb71b000>;
			interrupt-names = "hc_irq\0pwr_irq";
			interrupts = <0x00 0x7d 0x00 0x00 0xdd 0x00>;
			qcom,msm-bus,name = "sdhc2";
			qcom,cpu-dma-latency-us = <0x2bd>;
			qcom,vdd-current-level = <0x3a98 0x61a80>;
			qcom,disable-aggressive-pm;
			qcom,dedicated-io = <0x01>;
			compatible = "qcom,sdhci-msm";
			clock-names = "iface_clk\0core_clk";
			qcom,bus-bw-vectors-bps = <0x00 0x61a80 0x1312d00 0x17d7840 0x2faf080 0x5f5e100 0xbebc200 0xffffffff>;
		};

		dp1 {
			qcom,link-poll = <0x01>;
			qcom,mactype = <0x00>;
			local-mac-address = [32 38 38 30 41 32];
			phy-mode = "sgmii";
			reg = <0x3a001000 0x200>;
			device_type = "network";
			compatible = "qcom,nss-dp";
			qcom,id = <0x01>;
			qcom,phy-mdio-addr = <0x00>;
		};

		i2c@78b7000 {
			dma-names = "rx\0tx";
			clocks = <0x0b 0x54 0x0b 0x59>;
			#address-cells = <0x01>;
			dmas = <0x0e 0x11 0x0e 0x10>;
			reg = <0x78b7000 0x600>;
			status = "disabled";
			interrupts = <0x00 0x61 0x04>;
			compatible = "qcom,i2c-qup-v2.2.1";
			clock-names = "iface\0core";
			#size-cells = <0x00>;
			clock-frequency = <0x186a0>;
		};

		etm@619d000 {
			cpu = <0x4e>;
			clocks = <0x0b 0xee 0x0b 0xed>;
			reg = <0x619d000 0x1000>;
			coresight-name = "coresight-etm1";
			compatible = "arm,primecell";
			clock-names = "apb_pclk\0core_a_clk";
			arm,primecell-periphid = <0x3b95d>;

			port {

				endpoint {
					phandle = <0x49>;
					remote-endpoint = <0x4f>;
					linux,phandle = <0x49>;
				};
			};
		};

		gpio_keys {
			pinctrl-0 = <0x5e>;
			pinctrl-names = "default";
			compatible = "gpio-keys";

			button@1 {
				debounce-interval = <0x3c>;
				gpios = <0x1d 0x2f 0x01>;
				linux,code = <0x211>;
				linux,input-type = <0x01>;
				label = "wps";
			};

			button@2 {
				debounce-interval = <0x3c>;
				gpios = <0x1d 0x01 0x01>;
				linux,code = <0x198>;
				linux,input-type = <0x01>;
				label = "reset";
			};
		};

		edma@3ab00000 {
			reset-names = "edma_rst";
			resets = <0x0b 0x8a>;
			qcom,rxdesc-ring-start = <0x0f>;
			qcom,txcmpl-ring-start = <0x07>;
			qcom,txdesc-rings = <0x01>;
			reg = <0x3ab00000 0x76900>;
			qcom,rxfill-rings = <0x01>;
			qcom,txcmpl-rings = <0x01>;
			reg-names = "edma-reg-base";
			interrupts = <0x00 0x159 0x04 0x00 0x161 0x04 0x00 0x169 0x04 0x00 0x158 0x04>;
			compatible = "qcom,edma";
			qcom,rxdesc-rings = <0x01>;
			qcom,txdesc-ring-start = <0x17>;
			qcom,rxfill-ring-start = <0x07>;
		};

		phy@86000 {
			reset-names = "phy\0phy_phy";
			resets = <0x0b 0x4e 0x0b 0x4f>;
			phandle = <0x2a>;
			clocks = <0x0b 0xa4>;
			reg = <0x86000 0x1000>;
			#phy-cells = <0x00>;
			compatible = "qca,pcie-qmp-phy-gen2";
			clock-names = "pipe_clk";
			linux,phandle = <0x2a>;
		};

		tmc@6027000 {
			coresight-ctis = <0x34 0x35>;
			clocks = <0x0b 0xee 0x0b 0xed>;
			reg = <0x6027000 0x1000>;
			reg-names = "tmc-base";
			coresight-name = "coresight-tmc-etf";
			compatible = "arm,primecell";
			clock-names = "apb_pclk\0core_a_clk";
			arm,primecell-periphid = <0x3b961>;
			arm,default-sink;

			ports {
				#address-cells = <0x01>;
				#size-cells = <0x00>;

				port@0 {
					reg = <0x00>;

					endpoint {
						phandle = <0x38>;
						remote-endpoint = <0x39>;
						linux,phandle = <0x38>;
					};
				};

				port@1 {
					reg = <0x00>;

					endpoint {
						phandle = <0x3b>;
						slave-mode;
						remote-endpoint = <0x3a>;
						linux,phandle = <0x3b>;
					};
				};
			};
		};

		dummy-regulator@0 {
			regulator-always-on;
			regulator-boot-on;
			regulator-min-microvolt = <0xcf080>;
			regulator-name = "dummy-reg";
			compatible = "regulator-fixed";
			regulator-max-microvolt = <0xcf080>;
		};

		qca,tzlog {
			qca,hyp-enabled;
			interrupts = <0x00 0xf4 0x01>;
			compatible = "qca,tz64-hv-log";
			qca,tzbsp-diag-buf-size = <0x2000>;
		};

		cti@6017000 {
			clocks = <0x0b 0xee 0x0b 0xed>;
			reg = <0x6017000 0x1000>;
			reg-names = "cti-base";
			coresight-name = "coresight-cti7";
			compatible = "arm,coresight-cti";
			clock-names = "core_clk\0core_a_clk";
		};

		qcom,diag@0 {
			status = "ok";
			compatible = "qcom,diag";
		};

		qpic-nand@79b0000 {
			dma-names = "tx\0rx\0cmd";
			clocks = <0x0b 0xac 0x0b 0xab>;
			#address-cells = <0x01>;
			dmas = <0x24 0x00 0x24 0x01 0x24 0x02>;
			reg = <0x79b0000 0x10000>;
			status = "disabled";
			compatible = "qcom,ebi2-nandc-bam-v1.5.0";
			clock-names = "core\0aon";
			#size-cells = <0x00>;

			nandcs@0 {
				nand-bus-width = <0x08>;
				#address-cells = <0x01>;
				reg = <0x00>;
				nand-ecc-step-size = <0x200>;
				compatible = "qcom,nandcs";
				#size-cells = <0x01>;
				nand-ecc-strength = <0x04>;
			};
		};

		cpr4-ctrl@b018000 {
			qcom,apm-threshold-voltage = <0xcf080>;
			qcom,voltage-step = <0x1f40>;
			vdd-supply = <0x5b>;
			qcom,cpr-down-error-step-limit = <0x01>;
			qcom,apm-ctrl = <0x5a>;
			qcom,cpr-loop-time = <0x4c4b40>;
			qcom,cpr-step-quot-init-min = <0x0c>;
			qcom,cpr-up-error-step-limit = <0x01>;
			reg = <0xb018000 0x4000 0xa4000 0x1000 0x193d008 0x04>;
			qcom,cpr-idle-cycles = <0x0f>;
			reg-names = "cpr_ctrl\0fuse_base\0cpr_tcsr_reg";
			qcom,cpr-count-repeat = <0x0e>;
			qcom,cpr-count-mode = <0x00>;
			interrupt-names = "cpr";
			qcom,cpr-ctrl-name = "apc";
			interrupts = <0x00 0x0f 0x01>;
			compatible = "qcom,cpr4-ipq807x-apss-regulator";
			qcom,cpr-sensor-time = <0x3e8>;
			qcom,cpr-step-quot-init-max = <0x0e>;

			thread@0 {
				qcom,cpr-consecutive-down = <0x00>;
				qcom,cpr-down-threshold = <0x01>;
				qcom,cpr-consecutive-up = <0x00>;
				qcom,cpr-thread-id = <0x00>;
				qcom,cpr-up-threshold = <0x04>;

				regulator {
					qcom,cpr-open-loop-voltage-fuse-adjustment-0 = <0x00 0x00 0x00 0x00 0x00 0x00 0x00 0x00 0x00 0x00 0x00 0x00 0x00 0x00 0x00 0x2ee0 0x00 0x00 0x00 0x00 0x00 0x00 0x00 0x00 0x00 0x00 0x00 0x00 0x00 0x00 0x00 0x00>;
					qcom,cpr-scaled-open-loop-voltage-as-ceiling;
					qcom,cpr-part-types = <0x02>;
					qcom,cpr-speed-bins = <0x01>;
					qcom,cpr-closed-loop-voltage-adjustment-v2-0 = <0x00 0x00 0x00 0x00 0x00 0x00 0x00 0x00 0x00 0x00 0x00 0x00 0x00 0x00 0x00 0x00 0x00 0x00 0x00 0x00 0x00 0x00 0x00 0x00 0x00 0x00 0x00 0x00 0x00 0x00 0x00 0x00>;
					phandle = <0x06>;
					qcom,cpr-voltage-ceiling = <0xcd140 0xdcb40 0xe6780 0xf03c0 0xf2300 0x103c40>;
					qcom,cpr-parts-voltage-v2 = <0xf2300>;
					qcom,cpr-open-loop-voltage-fuse-adjustment-v2-1 = <0x00 0x00 0x00 0x00 0x00 0x1b58 0x8ca0 0xfa0 0x00 0x00 0x00 0x00 0x00 0x00 0x00 0x00 0x00 0x00 0x00 0x00 0x00 0x00 0x00 0x00 0x00 0x00 0x00 0x00 0x00 0x00 0x00 0x00>;
					qcom,cpr-fuse-corners = <0x04>;
					qcom,cpr-closed-loop-voltage-adjustment-v2-1 = <0x00 0x00 0x00 0x00 0x00 0x00 0x4a38 0x00 0x00 0x00 0x00 0x00 0x00 0x00 0x00 0x00 0x00 0x00 0x00 0x00 0x00 0x00 0x00 0x00 0x00 0x00 0x00 0x00 0x00 0x00 0x00 0x00>;
					qcom,cpr-ro-scaling-factor = <0xf82 0x1036 0x00 0x8e8 0x9d8 0x9a6 0x8ca 0x8e8 0x956 0x91a 0x9e2 0x9c4 0x352 0xb54 0x9ce 0x87a 0xf82 0x1036 0x00 0x8e8 0x9d8 0x9a6 0x8ca 0x8e8 0x956 0x91a 0x9e2 0x9c4 0x352 0xb54 0x9ce 0x87a 0xf82 0x1036 0x00 0x8e8 0x9d8 0x9a6 0x8ca 0x8e8 0x956 0x91a 0x9e2 0x9c4 0x352 0xb54 0x9ce 0x87a 0xf82 0x1036 0x00 0x8e8 0x9d8 0x9a6 0x8ca 0x8e8 0x956 0x91a 0x9e2 0x9c4 0x352 0xb54 0x9ce 0x87a>;
					qcom,cpr-corner-fmax-map = <0x01 0x03 0x05 0x06>;
					regulator-min-microvolt = <0x01>;
					qcom,allow-quotient-interpolation;
					qcom,cpr-parts-voltage = <0xffdc0>;
					qcom,cpr-fuse-combos = <0x08>;
					regulator-name = "apc_corner";
					regulator-max-microvolt = <0x06>;
					qcom,allow-voltage-interpolation;
					qcom,cpr-open-loop-voltage-fuse-adjustment-1 = <0x00 0x00 0x00 0x00 0x00 0x00 0x00 0x00 0x00 0x00 0x00 0x00 0x4e20 0x6590 0x00 0x4e20 0x00 0x00 0x00 0x00 0x00 0x00 0x00 0x00 0x00 0x00 0x00 0x00 0x00 0x00 0x00 0x00>;
					qcom,cpr-open-loop-voltage-fuse-adjustment-v2-0 = <0x00 0x00 0x00 0x00 0x00 0x00 0x00 0x00 0x00 0x00 0x00 0x00 0x00 0x00 0x00 0x00 0x00 0x00 0x00 0x00 0x00 0x00 0x00 0x00 0x00 0x00 0x00 0x00 0x00 0x00 0x00 0x00>;
					qcom,cpr-corners = <0x06>;
					qcom,cpr-floor-to-ceiling-max-range = <0x9c40 0x9c40 0x9c40 0x9c40 0x9c40 0x9c40 0x9c40 0x9c40 0x9c40 0x9c40 0x9c40 0x9c40 0x9c40 0x9c40 0x9c40 0x9c40 0x9c40 0x9c40 0x9c40 0x9c40 0x9c40 0x9c40 0x9c40 0x9c40 0x9c40 0x9c40 0x9c40 0x9c40 0x9c40 0x9c40 0x9c40 0x9c40 0x9c40 0x9c40 0x9c40 0x9c40 0x9c40 0x9c40 0x9c40 0x9c40 0x9c40 0x9c40 0x9c40 0x9c40 0x9c40 0x9c40 0x9c40 0x9c40>;
					linux,phandle = <0x06>;
					qcom,cpr-voltage-floor = <0x90880 0x9e340 0xadd40 0xb5a40 0xbf680 0xcf080>;
					qcom,cpr-speed-bin-corners = <0x06>;
					qcom,corner-frequencies = <0x3ca75800 0x5265c000 0x626b5000 0x6ddd0000 0x7270e000 0x839b6800>;
				};
			};
		};

		funnel@6021000 {
			clocks = <0x0b 0xee 0x0b 0xed>;
			reg = <0x6021000 0x1000>;
			reg-names = "funnel-base";
			coresight-name = "coresight-funnel-in0";
			compatible = "arm,primecell";
			clock-names = "apb_pclk\0core_a_clk";
			arm,primecell-periphid = <0x3b908>;

			ports {
				#address-cells = <0x01>;
				#size-cells = <0x00>;

				port@6 {
					reg = <0x00>;

					endpoint {
						phandle = <0x54>;
						slave-mode;
						remote-endpoint = <0x41>;
						linux,phandle = <0x54>;
					};
				};

				port@3 {
					reg = <0x05>;

					endpoint {
						phandle = <0x46>;
						slave-mode;
						remote-endpoint = <0x3e>;
						linux,phandle = <0x46>;
					};
				};

				port@0 {
					reg = <0x00>;

					endpoint {
						phandle = <0x3a>;
						remote-endpoint = <0x3b>;
						linux,phandle = <0x3a>;
					};
				};

				port@1 {
					reg = <0x03>;

					endpoint {
						phandle = <0x42>;
						slave-mode;
						remote-endpoint = <0x3c>;
						linux,phandle = <0x42>;
					};
				};

				port@5 {
					reg = <0x07>;

					endpoint {
						phandle = <0x55>;
						slave-mode;
						remote-endpoint = <0x40>;
						linux,phandle = <0x55>;
					};
				};

				port@4 {
					reg = <0x06>;

					endpoint {
						phandle = <0x57>;
						slave-mode;
						remote-endpoint = <0x3f>;
						linux,phandle = <0x57>;
					};
				};

				port@2 {
					reg = <0x04>;

					endpoint {
						phandle = <0x44>;
						slave-mode;
						remote-endpoint = <0x3d>;
						linux,phandle = <0x44>;
					};
				};
			};
		};

		wifi3@f00000 {
			mhi,max-channels = <0x1e>;
			qcom,wlan-ramdump-dynamic = <0x400000>;
			status = "disabled";
			mhi,timeout = <0x2710>;
			qrtr_node_id = <0x21>;
			compatible = "qcom,cnss-qcn9000";
			qca,auto-restart;
		};

		qcom,sps {
			compatible = "qcom,msm_sps_4k";
			qcom,pipe-attr-ee;
		};

		qcom,gcc@1800000 {
			phandle = <0x0b>;
			#clock-cells = <0x01>;
			reg = <0x1800000 0x80000>;
			compatible = "qcom,gcc-ipq807x";
			#reset-cells = <0x01>;
			linux,phandle = <0x0b>;
		};

		serial@78B3000 {
			pinctrl-0 = <0x0d>;
			tx-watermark = <0x00>;
			clocks = <0x0b 0x65 0x0b 0x54>;
			reg = <0x78b3000 0x200>;
			pinctrl-names = "default";
			status = "ok";
			interrupts = <0x00 0x134 0x00>;
			compatible = "qcom,msm-uartdm-v1.4\0qcom,msm-uartdm";
			clock-names = "core\0iface";
		};

		cti@6013000 {
			clocks = <0x0b 0xee 0x0b 0xed>;
			reg = <0x6013000 0x1000>;
			reg-names = "cti-base";
			coresight-name = "coresight-cti3";
			compatible = "arm,coresight-cti";
			clock-names = "core_clk\0core_a_clk";
		};

		clock-controller@b198000 {
			phandle = <0x07>;
			reg = <0xb198000 0x1000>;
			compatible = "qcom,arm-cortex-acc";
			linux,phandle = <0x07>;
		};

		cti@601d000 {
			clocks = <0x0b 0xee 0x0b 0xed>;
			reg = <0x601d000 0x1000>;
			reg-names = "cti-base";
			coresight-name = "coresight-cti13";
			compatible = "arm,coresight-cti";
			clock-names = "core_clk\0core_a_clk";
		};

		ssphy@58000 {
			reset-names = "usb3_phy_reset\0usb3phy_phy_reset";
			resets = <0x0b 0x2c 0x0b 0x2d>;
			qcom,qmp-phy-reg-offset = <0x988 0x98c 0x990 0x994 0x974 0x8d8 0x8dc 0x804 0x800 0x808>;
			phandle = <0x29>;
			clocks = <0x0b 0xcb 0x0b 0xcf>;
			reg = <0x58000 0x45c 0x8cf8800 0x100 0x5e000 0x18>;
			qcom,qmp-phy-init-seq = <0xac 0x14 0x1a 0x00 0x34 0x08 0x08 0x00 0x174 0x30 0x30 0x00 0x3c 0x06 0x06 0x00 0xb4 0x00 0x00 0x00 0xb8 0x08 0x08 0x00 0x194 0x06 0x06 0x3e8 0x19c 0x01 0x01 0x00 0x178 0x00 0x00 0x00 0xd0 0x82 0x82 0x00 0xdc 0x55 0x55 0x00 0xe0 0x55 0x55 0x00 0xe4 0x03 0x03 0x00 0x78 0x0b 0x0b 0x00 0x84 0x16 0x16 0x00 0x90 0x28 0x28 0x00 0x108 0x80 0x80 0x00 0x10c 0x00 0x00 0x00 0x184 0x0a 0x0a 0x00 0x4c 0x15 0x15 0x00 0x50 0x34 0x34 0x00 0x54 0x00 0x00 0x00 0xc8 0x00 0x00 0x00 0x18c 0x00 0x00 0x00 0xcc 0x00 0x00 0x00 0x128 0x00 0x00 0x00 0x0c 0x0a 0x0a 0x00 0x10 0x01 0x01 0x00 0x1c 0x31 0x31 0x00 0x20 0x01 0x01 0x00 0x14 0x00 0x00 0x00 0x18 0x00 0x00 0x00 0x24 0xde 0xde 0x00 0x28 0x07 0x07 0x00 0x48 0x0f 0x0f 0x00 0x70 0x0f 0x0f 0x00 0x100 0x80 0x80 0x00 0x440 0x0b 0x0b 0x00 0x4d8 0x02 0x02 0x00 0x4dc 0x6c 0x6c 0x00 0x4e0 0xbb 0xb8 0x00 0x508 0x77 0x77 0x00 0x50c 0x80 0x80 0x00 0x514 0x03 0x03 0x00 0x51c 0x16 0x16 0x00 0x448 0x75 0x75 0x00 0x454 0x00 0x00 0x00 0x40c 0x0a 0x0a 0x00 0x41c 0x06 0x06 0x00 0x510 0x00 0x00 0x00 0x268 0x45 0x45 0x00 0x2ac 0x12 0x12 0x00 0x294 0x06 0x06 0x00 0x254 0x00 0x00 0x00 0x8c8 0x83 0x83 0x00 0x8c4 0x02 0x02 0x00 0x8cc 0x09 0x09 0x00 0x8d0 0xa2 0xa2 0x00 0x8d4 0x85 0x85 0x00 0x880 0xd1 0xd1 0x00 0x884 0x1f 0x1f 0x00 0x888 0x47 0x47 0x00 0x80c 0x9f 0x9f 0x00 0x824 0x17 0x17 0x00 0x828 0x0f 0x0f 0x00 0x8b8 0x75 0x75 0x00 0x8bc 0x13 0x13 0x00 0x8b0 0x86 0x86 0x00 0x8a0 0x04 0x04 0x00 0x88c 0x44 0x44 0x00 0x870 0xe7 0xe7 0x00 0x874 0x03 0x03 0x00 0x878 0x40 0x40 0x00 0x87c 0x00 0x00 0x00 0x9d8 0x88 0x88 0x00 0xffffffff 0xffffffff 0x00 0x00>;
			status = "ok";
			reg-names = "qmp_phy_base\0qscratch_base\0ahb2phy_base";
			compatible = "qcom,usb-ssphy-qmp";
			clock-names = "aux_clk\0pipe_clk";
			linux,phandle = <0x29>;
		};

		npu-cpr {
			qcom,voltage-step = <0x1f40>;
			vdd-supply = <0x5c>;
			reg = <0xa4000 0x1000 0x193d008 0x04>;
			reg-names = "fuse_base\0cpr_tcsr_reg";
			qcom,cpr-ctrl-name = "npu";
			compatible = "qcom,cpr3-ipq807x-npu-regulator";

			thread@0 {
				qcom,cpr-consecutive-down = <0x02>;
				qcom,cpr-down-threshold = <0x01>;
				qcom,cpr-consecutive-up = <0x00>;
				qcom,cpr-thread-id = <0x00>;
				qcom,cpr-up-threshold = <0x02>;

				regulator {
					qcom,cpr-cold-temp-threshold-v2 = <0x1e>;
					qcom,cpr-open-loop-voltage-fuse-adjustment-0 = <0x9c40 0x9c40>;
					qcom,cpr-part-types = <0x02>;
					qcom,cpr-speed-bins = <0x01>;
					phandle = <0x20>;
					qcom,cpr-voltage-ceiling = <0xdea80 0xf2300>;
					qcom,cpr-cold-temp-voltage-adjustment-v2-1 = <0x88b8 0x6978>;
					qcom,cpr-parts-voltage-v2 = <0xcb201>;
					qcom,cpr-open-loop-voltage-fuse-adjustment-v2-1 = <0x9c40 0x9c40>;
					qcom,cpr-fuse-corners = <0x02>;
					qcom,cpr-cold-temp-voltage-adjustment-v2-0 = <0x00 0x00>;
					qcom,cpr-corner-fmax-map = <0x01 0x02>;
					regulator-min-microvolt = <0x01>;
					qcom,cpr-parts-voltage = <0xec540>;
					qcom,cpr-fuse-combos = <0x01>;
					regulator-name = "npu_corner";
					regulator-max-microvolt = <0x03>;
					qcom,allow-voltage-interpolation;
					qcom,cpr-open-loop-voltage-fuse-adjustment-1 = <0x5dc0 0x5dc0>;
					qcom,cpr-open-loop-voltage-fuse-adjustment-v2-0 = <0x9c40 0x9c40>;
					qcom,cpr-corners = <0x02>;
					linux,phandle = <0x20>;
					qcom,cpr-voltage-floor = <0xb7980 0xc15c0>;
					qcom,cpr-speed-bin-corners = <0x02>;
					qcom,corner-frequencies = <0x59439000 0x64b54000>;
				};
			};
		};

		mailbox@b111000 {
			#mbox-cells = <0x01>;
			phandle = <0x1f>;
			compatible = "qcom,msm8996-apcs-hmss-global";
			qcom,ipc = <0x18 0x08 0x08>;
			linux,phandle = <0x1f>;
		};

		pci@20000000 {
			linux,pci-domain = <0x00>;
			reset-names = "pipe\0sleep\0sticky\0axi_m\0axi_s\0ahb\0axi_m_sticky\0axi_s_sticky";
			resets = <0x0b 0x75 0x0b 0x76 0x0b 0x77 0x0b 0x78 0x0b 0x79 0x0b 0x7a 0x0b 0x7b 0x0b 0x7b>;
			pinctrl-0 = <0x2c 0x2d>;
			e911-gpio = <0x1d 0x21 0x00>;
			clocks = <0x0b 0xe9 0x0b 0xa2 0x0b 0xa3 0x0b 0xa0 0x0b 0xa1 0x0b 0xf5 0x0b 0xf6>;
			phy-names = "pciephy-gen2\0pciephy-gen3";
			perst-gpio = <0x1d 0x3a 0x01>;
			interrupts-extended = <0x01 0x00 0x34 0x00 0x01 0x00 0x1a0 0x00 0x01 0x00 0x1a1 0x00 0x01 0x00 0x1a2 0x00 0x01 0x00 0x1a3 0x00 0x01 0x00 0x1a4 0x00 0x01 0x00 0x1a5 0x00 0x01 0x00 0x1a6 0x00 0x01 0x00 0x1a7 0x00 0x01 0x00 0x1a8 0x00 0x01 0x00 0x1a9 0x00 0x01 0x00 0x1aa 0x00 0x01 0x00 0x1ab 0x00 0x01 0x00 0x1ac 0x00 0x01 0x00 0x1ad 0x00 0x01 0x00 0x1ae 0x00 0x01 0x00 0x1af 0x00 0x1d 0x3b 0x00 0x1d 0x21 0x00>;
			ranges = <0x81000000 0x00 0x20200000 0x20200000 0x00 0x10000 0x82000000 0x00 0x20220000 0x20220000 0x00 0xfde0000>;
			#address-cells = <0x03>;
			use_delay = <0x00>;
			reg = <0x20000000 0xf1d 0x20000f20 0xa8 0x20001000 0x1000 0x80000 0x2000 0x20100000 0x1000>;
			pinctrl-names = "default";
			status = "ok";
			#interrupt-cells = <0x01>;
			bus-range = <0x00 0xff>;
			interrupt-map = <0x00 0x00 0x00 0x01 0x01 0x00 0x4b 0x04 0x00 0x00 0x00 0x02 0x01 0x00 0x4e 0x04 0x00 0x00 0x00 0x03 0x01 0x00 0x4f 0x04 0x00 0x00 0x00 0x04 0x01 0x00 0x53 0x04>;
			reg-names = "dbi\0elbi\0dm_iatu\0parf\0config";
			interrupt-names = "msi\0msi_0\0msi_1\0msi_2\0msi_3\0msi_4\0msi_5\0msi_6\0msi_7\0msi_8\0msi_9\0msi_10\0msi_11\0msi_12\0msi_13\0msi_14\0msi_15\0wake_gpio\0mdm2ap_e911";
			num-lanes = <0x01>;
			device_type = "pci";
			interrupts = <0x00 0x34 0x00 0x00 0x1a0 0x00 0x00 0x1a1 0x00 0x00 0x1a2 0x00 0x00 0x1a3 0x00 0x00 0x1a4 0x00 0x00 0x1a5 0x00 0x00 0x1a6 0x00 0x00 0x1a7 0x00 0x00 0x1a8 0x00 0x00 0x1a9 0x00 0x00 0x1aa 0x00 0x00 0x1ab 0x00 0x00 0x1ac 0x00 0x00 0x1ad 0x00 0x00 0x1ae 0x00 0x00 0x1af 0x00>;
			phys = <0x2a 0x2b>;
			compatible = "qcom,pcie-ipq807x";
			clock-names = "sys_noc\0axi_m\0axi_s\0ahb\0aux\0axi_bridge\0rchng";
			interrupt-map-mask = <0x00 0x00 0x00 0x07>;
			qcom,msi-gicm-base = <0x1c0>;
			#size-cells = <0x02>;
			link_retries_count = <0x64>;
			qcom,msi-gicm-addr = <0xb00a040>;

			pcie0_rp {
				#address-cells = <0x05>;
				reg = <0x00 0x00 0x00 0x00 0x00>;
				status = "ok";
				#size-cells = <0x00>;

				aliases {
					mhi-netdev0 = "/soc/pci@20000000/pcie0_rp/qcom,mhi@0/mhi_devices/mhi_rmnet@0";
					mhi_netdev2 = "/soc/pci@20000000/pcie0_rp/qcom,mhi@0/mhi_devices/mhi_rmnet@2";
				};

				qcom,mhi@0 {
					mhi,max-channels = <0x6e>;
					pinctrl-0 = <0x2e>;
					ap2mdm = <0x1a>;
					reg = <0x00 0x00 0x00 0x00 0x00>;
					pinctrl-names = "default";
					qcom,iommu-dma = "disabled";
					mhi,timeout = <0xea60>;
					mhi,ssr-negotiate;
					mdm2ap = <0x19>;

					mhi_devices {
						#address-cells = <0x01>;
						#size-cells = <0x00>;

						mhi_qrtr {
							qcom,net-id = <0x03>;
							mhi,chan = "IPCR";
						};

						mhi_rmnet@1 {
							mhi,chan = "IP_HW0_RSC";
							reg = <0x01>;
							mhi,rsc-parent = <0x2f>;
							mhi,mru = <0x8000>;
						};

						mhi_rmnet@2 {
							mhi,chan = "IP_SW0";
							reg = <0x02>;
							mhi,disable-chain-skb;
							mhi,interface-name = "rmnet_mhi_sw";
							mhi,mru = <0x4000>;
						};

						mhi_rmnet@0 {
							phandle = <0x2f>;
							mhi,chan = "IP_HW0";
							reg = <0x00>;
							mhi,chain-skb;
							linux,phandle = <0x2f>;
							mhi,interface-name = "rmnet_mhi";
							mhi,mru = <0x4000>;
						};
					};

					mhi_channels {
						#address-cells = <0x01>;
						#size-cells = <0x00>;

						mhi_chan@5 {
							mhi,chan-dir = <0x02>;
							mhi,num-elements = <0x40>;
							mhi,event-ring = <0x03>;
							reg = <0x05>;
							mhi,data-type = <0x00>;
							mhi,doorbell-mode = <0x02>;
							label = "DIAG";
							mhi,ee = <0x04>;
						};

						mhi_chan@18 {
							mhi,chan-dir = <0x01>;
							mhi,num-elements = <0x40>;
							mhi,event-ring = <0x01>;
							reg = <0x12>;
							mhi,data-type = <0x00>;
							mhi,doorbell-mode = <0x02>;
							label = "IP_CTRL";
							mhi,ee = <0x04>;
						};

						mhi_chan@47 {
							mhi,chan-dir = <0x02>;
							mhi,num-elements = <0x200>;
							mhi,event-ring = <0x05>;
							reg = <0x2f>;
							mhi,data-type = <0x04>;
							mhi,doorbell-mode = <0x02>;
							label = "IP_SW0";
							mhi,ee = <0x04>;
						};

						mhi_chan@21 {
							mhi,chan-dir = <0x02>;
							mhi,num-elements = <0x40>;
							mhi,event-ring = <0x02>;
							mhi,auto-queue;
							reg = <0x15>;
							mhi,data-type = <0x00>;
							mhi,auto-start;
							mhi,doorbell-mode = <0x02>;
							label = "IPCR";
							mhi,ee = <0x04>;
						};

						mhi_chan@46 {
							mhi,chan-dir = <0x01>;
							mhi,num-elements = <0x200>;
							mhi,event-ring = <0x04>;
							reg = <0x2e>;
							mhi,data-type = <0x01>;
							mhi,doorbell-mode = <0x02>;
							label = "IP_SW0";
							mhi,ee = <0x04>;
						};

						mhi_chan@106 {
							mhi,chan-dir = <0x02>;
							mhi,num-elements = <0x80>;
							mhi,event-ring = <0x0b>;
							reg = <0x6a>;
							mhi,data-type = <0x00>;
							mhi,doorbell-mode = <0x02>;
							label = "RMNET_CTL";
							mhi,ee = <0x04>;
						};

						mhi_chan@20 {
							mhi,chan-dir = <0x01>;
							mhi,num-elements = <0x40>;
							mhi,event-ring = <0x02>;
							reg = <0x14>;
							mhi,data-type = <0x01>;
							mhi,auto-start;
							mhi,doorbell-mode = <0x02>;
							label = "IPCR";
							mhi,ee = <0x04>;
						};

						mhi_chan@105 {
							mhi,chan-dir = <0x01>;
							mhi,num-elements = <0x80>;
							mhi,event-ring = <0x0a>;
							reg = <0x69>;
							mhi,data-type = <0x01>;
							mhi,doorbell-mode = <0x02>;
							label = "RMNET_CTL";
							mhi,ee = <0x04>;
						};

						mhi_chan@16 {
							mhi,chan-dir = <0x01>;
							mhi,num-elements = <0x40>;
							mhi,event-ring = <0x03>;
							reg = <0x10>;
							mhi,data-type = <0x00>;
							mhi,doorbell-mode = <0x02>;
							label = "QMI1";
							mhi,ee = <0x04>;
						};

						mhi_chan@0 {
							mhi,chan-dir = <0x01>;
							mhi,num-elements = <0x40>;
							mhi,event-ring = <0x02>;
							reg = <0x00>;
							mhi,data-type = <0x00>;
							mhi,doorbell-mode = <0x02>;
							label = "LOOPBACK";
							mhi,ee = <0x04>;
						};

						mhi_chan@19 {
							mhi,chan-dir = <0x02>;
							mhi,num-elements = <0x40>;
							mhi,event-ring = <0x01>;
							mhi,auto-queue;
							reg = <0x13>;
							mhi,data-type = <0x00>;
							mhi,doorbell-mode = <0x02>;
							label = "IP_CTRL";
							mhi,ee = <0x04>;
						};

						mhi_chan@102 {
							mhi,chan-dir = <0x02>;
							mhi,event-ring = <0x08>;
							mhi,offload-chan;
							reg = <0x66>;
							mhi,data-type = <0x03>;
							label = "IP_HW_ADPL";
							mhi,ee = <0x04>;
							mhi,lpm-notify;
						};

						mhi_chan@100 {
							mhi,chan-dir = <0x01>;
							mhi,num-elements = <0x200>;
							mhi,event-ring = <0x06>;
							mhi,db-mode-switch;
							reg = <0x64>;
							mhi,data-type = <0x01>;
							mhi,doorbell-mode = <0x03>;
							label = "IP_HW0";
							mhi,ee = <0x04>;
						};

						mhi_chan@14 {
							mhi,chan-dir = <0x01>;
							mhi,num-elements = <0x40>;
							mhi,event-ring = <0x01>;
							reg = <0x0e>;
							mhi,data-type = <0x00>;
							mhi,doorbell-mode = <0x02>;
							label = "QMI0";
							mhi,ee = <0x04>;
						};

						mhi_chan@4 {
							mhi,chan-dir = <0x01>;
							mhi,num-elements = <0x40>;
							mhi,event-ring = <0x01>;
							reg = <0x04>;
							mhi,data-type = <0x00>;
							mhi,doorbell-mode = <0x02>;
							label = "DIAG";
							mhi,ee = <0x04>;
						};

						mhi_chan@17 {
							mhi,chan-dir = <0x02>;
							mhi,num-elements = <0x40>;
							mhi,event-ring = <0x03>;
							reg = <0x11>;
							mhi,data-type = <0x00>;
							mhi,doorbell-mode = <0x02>;
							label = "QMI1";
							mhi,ee = <0x04>;
						};

						mhi_chan@1 {
							mhi,chan-dir = <0x02>;
							mhi,num-elements = <0x40>;
							mhi,event-ring = <0x02>;
							reg = <0x01>;
							mhi,data-type = <0x00>;
							mhi,doorbell-mode = <0x02>;
							label = "LOOPBACK";
							mhi,ee = <0x04>;
						};

						mhi_chan@15 {
							mhi,chan-dir = <0x02>;
							mhi,num-elements = <0x40>;
							mhi,event-ring = <0x02>;
							reg = <0x0f>;
							mhi,data-type = <0x00>;
							mhi,doorbell-mode = <0x02>;
							label = "QMI0";
							mhi,ee = <0x04>;
						};

						mhi_chan@101 {
							mhi,chan-dir = <0x02>;
							mhi,num-elements = <0x200>;
							mhi,event-ring = <0x07>;
							reg = <0x65>;
							mhi,data-type = <0x04>;
							mhi,doorbell-mode = <0x03>;
							label = "IP_HW0";
							mhi,ee = <0x04>;
						};
					};

					mhi_events {
						#address-cells = <0x01>;
						#size-cells = <0x00>;

						mhi_event@6 {
							mhi,num-elements = <0x400>;
							mhi,chan = <0x64>;
							mhi,priority = <0x01>;
							mhi,brstmode = <0x03>;
							mhi,msi = <0x05>;
							mhi,intmod = <0x05>;
							mhi,hw-ev;
						};

						mhi_event@5 {
							mhi,num-elements = <0x400>;
							mhi,chan = <0x2f>;
							mhi,priority = <0x01>;
							mhi,client-manage;
							mhi,brstmode = <0x02>;
							mhi,msi = <0x06>;
							mhi,intmod = <0x05>;
						};

						mhi_event@4 {
							mhi,num-elements = <0x400>;
							mhi,chan = <0x2e>;
							mhi,priority = <0x01>;
							mhi,brstmode = <0x02>;
							mhi,msi = <0x05>;
							mhi,intmod = <0x05>;
						};

						mhi_event@2 {
							mhi,num-elements = <0x100>;
							mhi,priority = <0x01>;
							mhi,brstmode = <0x02>;
							mhi,msi = <0x03>;
							mhi,intmod = <0x01>;
						};

						mhi_event@1 {
							mhi,num-elements = <0x100>;
							mhi,priority = <0x01>;
							mhi,brstmode = <0x02>;
							mhi,msi = <0x02>;
							mhi,intmod = <0x01>;
						};

						mhi_event@12 {
							mhi,offload;
							mhi,num-elements = <0x00>;
							mhi,chan = <0x6b>;
							mhi,priority = <0x01>;
							mhi,client-manage;
							mhi,brstmode = <0x03>;
							mhi,msi = <0x00>;
							mhi,intmod = <0x00>;
							mhi,hw-ev;
						};

						mhi_event@13 {
							mhi,offload;
							mhi,num-elements = <0x00>;
							mhi,chan = <0x6c>;
							mhi,priority = <0x01>;
							mhi,client-manage;
							mhi,brstmode = <0x03>;
							mhi,msi = <0x00>;
							mhi,intmod = <0x00>;
							mhi,hw-ev;
						};

						mhi_event@10 {
							mhi,num-elements = <0x400>;
							mhi,chan = <0x69>;
							mhi,priority = <0x00>;
							mhi,brstmode = <0x02>;
							mhi,msi = <0x08>;
							mhi,intmod = <0x01>;
							mhi,hw-ev;
						};

						mhi_event@7 {
							mhi,num-elements = <0x400>;
							mhi,chan = <0x65>;
							mhi,priority = <0x01>;
							mhi,client-manage;
							mhi,brstmode = <0x03>;
							mhi,msi = <0x06>;
							mhi,intmod = <0x05>;
							mhi,hw-ev;
						};

						mhi_event@8 {
							mhi,offload;
							mhi,num-elements = <0x00>;
							mhi,chan = <0x66>;
							mhi,priority = <0x01>;
							mhi,client-manage;
							mhi,brstmode = <0x03>;
							mhi,msi = <0x00>;
							mhi,intmod = <0x00>;
							mhi,hw-ev;
						};

						mhi_event@3 {
							mhi,num-elements = <0x100>;
							mhi,priority = <0x01>;
							mhi,brstmode = <0x02>;
							mhi,msi = <0x04>;
							mhi,intmod = <0x01>;
						};

						mhi_event@0 {
							mhi,num-elements = <0x20>;
							mhi,priority = <0x01>;
							reg = <0x00>;
							mhi,data-type = <0x01>;
							mhi,brstmode = <0x02>;
							mhi,msi = <0x01>;
							mhi,intmod = <0x01>;
						};

						mhi_event@9 {
							mhi,num-elements = <0x400>;
							mhi,chan = <0x67>;
							mhi,priority = <0x01>;
							mhi,brstmode = <0x02>;
							mhi,msi = <0x07>;
							mhi,intmod = <0x05>;
							mhi,hw-ev;
						};

						mhi_event@11 {
							mhi,num-elements = <0x400>;
							mhi,chan = <0x6a>;
							mhi,priority = <0x00>;
							mhi,brstmode = <0x02>;
							mhi,msi = <0x09>;
							mhi,intmod = <0x00>;
							mhi,hw-ev;
						};
					};
				};
			};
		};

		clock-controller@b1a8000 {
			phandle = <0x09>;
			reg = <0xb1a8000 0x1000>;
			compatible = "qcom,arm-cortex-acc";
			linux,phandle = <0x09>;
		};

		mdio@90000 {
			pinctrl-0 = <0x1c>;
			phy-reset-gpio = <0x1d 0x25 0x00>;
			#address-cells = <0x01>;
			reg = <0x90000 0x64>;
			pinctrl-names = "default";
			compatible = "qcom,ipq40xx-mdio";
			#size-cells = <0x01>;

			ethernet-phy@1 {
				reg = <0x01>;
			};

			ethernet-phy@2 {
				reg = <0x02>;
			};

			ethernet-phy@3 {
				reg = <0x03>;
			};

			ethernet-phy@4 {
				reg = <0x04>;
			};

			ethernet-phy@0 {
				reg = <0x00>;
			};

			ethernet-phy@5 {
				reg = <0x07>;
				compatible = "ethernet-phy-ieee802.3-c45";
			};
		};

		spi@78b5000 {
			pinctrl-0 = <0x0f>;
			dma-names = "tx\0rx";
			clocks = <0x0b 0x56 0x0b 0x54>;
			#address-cells = <0x01>;
			dmas = <0x0e 0x0c 0x0e 0x0d>;
			reg = <0x78b5000 0x600>;
			cs-select = <0x00>;
			pinctrl-names = "default";
			status = "ok";
			interrupts = <0x00 0x5f 0x00>;
			spi-max-frequency = <0x2faf080>;
			compatible = "qcom,spi-qup-v2.2.1";
			clock-names = "core\0iface";
			#size-cells = <0x00>;

			m25p80@0 {
				density = <0x1000000>;
				sector-size = <0x10000>;
				#address-cells = <0x01>;
				reg = <0x00>;
				use-default-sizes;
				spi-max-frequency = <0x2faf080>;
				compatible = "n25q128a11";
				linux,modalias = "m25p80\0n25q128a11";
				#size-cells = <0x01>;

				partition@3b0000 {
					reg = <0x3b0000 0x10000>;
					label = "0:DEVCFG";
				};

				partition@0 {
					reg = <0x00 0x50000>;
					label = "0:SBL1";
				};

				partition@460000 {
					reg = <0x460000 0x10000>;
					label = "0:CDT_1";
				};

				partition@80000 {
					reg = <0x80000 0x20000>;
					label = "0:BOOTCONFIG1";
				};

				partition@470000 {
					reg = <0x470000 0x10000>;
					label = "0:CDT";
				};

				partition@610000 {
					reg = <0x610000 0x80000>;
					label = "0:ETHPHYFW";
				};

				partition@5d0000 {
					reg = <0x5d0000 0x40000>;
					label = "0:ART";
				};

				partition@480000 {
					reg = <0x480000 0x10000>;
					label = "0:APPSBLENV";
				};

				partition@220000 {
					reg = <0x220000 0x180000>;
					label = "0:QSEE";
				};

				partition@3a0000 {
					reg = <0x3a0000 0x10000>;
					label = "0:DEVCFG_1";
				};

				partition@490000 {
					reg = <0x490000 0xa0000>;
					label = "0:APPSBL_1";
				};

				partition@3c0000 {
					reg = <0x3c0000 0x10000>;
					label = "0:APDP";
				};

				partition@3e0000 {
					reg = <0x3e0000 0x40000>;
					label = "0:RPM_1";
				};

				partition@60000 {
					reg = <0x60000 0x20000>;
					label = "0:BOOTCONFIG";
				};

				partition@420000 {
					reg = <0x420000 0x40000>;
					label = "0:RPM";
				};

				partition@3d0000 {
					reg = <0x3d0000 0x10000>;
					label = "0:APDP_1";
				};

				partition@530000 {
					reg = <0x530000 0xa0000>;
					label = "0:APPSBL";
				};

				partition@50000 {
					reg = <0x50000 0x10000>;
					label = "0:MIBIB";
				};

				partition@a0000 {
					reg = <0xa0000 0x180000>;
					label = "0:QSEE_1";
				};
			};
		};

		pinctrl@1000000 {
			pinctrl-0 = <0x0c>;
			phandle = <0x1d>;
			gpio-controller;
			reg = <0x1000000 0x300000>;
			pinctrl-names = "default";
			#interrupt-cells = <0x02>;
			interrupt-controller;
			#gpio-cells = <0x02>;
			interrupts = <0x00 0xd0 0x00>;
			compatible = "qcom,ipq807x-pinctrl";
			linux,phandle = <0x1d>;

			pcie0_wake_gpio {
				function = "pcie0_wake";
				drive-strength = <0x08>;
				phandle = <0x2c>;
				pins = "gpio59";
				bias-pull-up;
				linux,phandle = <0x2c>;
			};

			mdio_pinmux {
				phandle = <0x1c>;
				linux,phandle = <0x1c>;

				mux_1 {
					function = "mdio";
					drive-strength = <0x08>;
					pins = "gpio69";
					bias-pull-up;
				};

				mux_0 {
					function = "mdc";
					drive-strength = <0x08>;
					pins = "gpio68";
					bias-disable;
				};

				mux_4 {
					function = "gpio";
					drive-strength = <0x08>;
					pins = "gpio50";
					bias-pull-up;
				};
			};

			uart_pins {
				phandle = <0x0d>;
				linux,phandle = <0x0d>;

				mux {
					function = "blsp4_uart1";
					drive-strength = <0x08>;
					pins = "gpio23\0gpio24";
					bias-pull-up;
				};
			};

			mdm2ap_e911_status {
				drive-strength = <0x08>;
				phandle = <0x2d>;
				pins = "gpio33";
				linux,phandle = <0x2d>;
				bias-pull-down;
			};

			spi_0_pins {
				phandle = <0x0f>;
				linux,phandle = <0x0f>;

				mux {
					function = "blsp0_spi";
					drive-strength = <0x08>;
					pins = "gpio38\0gpio39\0gpio40\0gpio41";
					bias-pull-up;
				};
			};

			fan_en_gpio {
				phandle = <0x5d>;
				linux,phandle = <0x5d>;

				mux {
					function = "gpio";
					drive-strength = <0x08>;
					pins = "gpio8";
					bias-pull-up;
				};
			};

			button_pins {
				phandle = <0x5e>;
				linux,phandle = <0x5e>;

				wps_button {
					function = "gpio";
					drive-strength = <0x08>;
					pins = "gpio47";
					bias-pull-up;
				};

				reset_button {
					function = "gpio";
					drive-strength = <0x08>;
					pins = "gpio1";
					bias-pull-up;
				};
			};

			pwm_pinmux {
				phandle = <0x33>;
				linux,phandle = <0x33>;

				mux_1 {
					function = "pwm01";
					drive-strength = <0x08>;
					pins = "gpio63";
				};
			};

			ap2mdm_status {
				function = "gpio";
				drive-strength = <0x08>;
				phandle = <0x2e>;
				pins = "gpio26";
				bias-pull-up;
				linux,phandle = <0x2e>;
				output-high;
			};

			pcie_sdx_gpio {
				phandle = <0x0c>;
				linux,phandle = <0x0c>;

				ap2mdm_err_ftl {
					function = "gpio";
					drive-strength = <0x08>;
					pins = "gpio27";
					bias-pull-down;
				};

				sdx_pon_gpio {
					function = "gpio";
					drive-strength = <0x08>;
					pins = "gpio5";
					bias-pull-up;
					output-high;
				};
			};
		};

		nss-common {
			reg = <0x1868010 0x1000>;
			reg-names = "nss-misc-reset";
			compatible = "qcom,nss-common";
		};

		qcom_mdss_qpic_panel {
			qcom,mdss-pan-res = <0x320 0x1e0>;
			qcom,refresh_rate = <0x3c>;
			status = "disabled";
			compatible = "qcom,mdss-qpic-panel";
			qcom,mdss-pan-bpp = <0x12>;
			label = "qpic lcd panel";
		};

		interrupt-controller@b000000 {
			phandle = <0x01>;
			reg = <0xb000000 0x1000 0xb002000 0x1000>;
			#interrupt-cells = <0x03>;
			interrupt-controller;
			compatible = "qcom,msm-qgic2";
			linux,phandle = <0x01>;
		};

		wifi@c0000000 {
			reg = <0xc000000 0x2000000>;
			qcom,caldb-size = <0x480000>;
			status = "ok";
			qcom,tgt-mem-mode = <0x00>;
			interrupt-names = "misc-pulse1\0misc-latch\0sw-exception\0watchdog\0ce0\0ce1\0ce2\0ce3\0ce4\0ce5\0ce6\0ce7\0ce8\0ce9\0ce10\0ce11\0host2wbm-desc-feed\0host2reo-re-injection\0host2reo-command\0host2rxdma-monitor-ring3\0host2rxdma-monitor-ring2\0host2rxdma-monitor-ring1\0reo2ost-exception\0wbm2host-rx-release\0reo2host-status\0reo2host-destination-ring4\0reo2host-destination-ring3\0reo2host-destination-ring2\0reo2host-destination-ring1\0rxdma2host-monitor-destination-mac3\0rxdma2host-monitor-destination-mac2\0rxdma2host-monitor-destination-mac1\0ppdu-end-interrupts-mac3\0ppdu-end-interrupts-mac2\0ppdu-end-interrupts-mac1\0rxdma2host-monitor-status-ring-mac3\0rxdma2host-monitor-status-ring-mac2\0rxdma2host-monitor-status-ring-mac1\0host2rxdma-host-buf-ring-mac3\0host2rxdma-host-buf-ring-mac2\0host2rxdma-host-buf-ring-mac1\0rxdma2host-destination-ring-mac3\0rxdma2host-destination-ring-mac2\0rxdma2host-destination-ring-mac1\0host2tcl-input-ring4\0host2tcl-input-ring3\0host2tcl-input-ring2\0host2tcl-input-ring1\0wbm2host-tx-completions-ring3\0wbm2host-tx-completions-ring2\0wbm2host-tx-completions-ring1\0tcl2host-status-ring";
			qcom,caldb-addr = <0x4ba00000 0x4ba00000 0x00>;
			interrupts = <0x00 0x140 0x01 0x00 0x13f 0x01 0x00 0x13e 0x01 0x00 0x13d 0x01 0x00 0x13c 0x01 0x00 0x13b 0x01 0x00 0x13a 0x01 0x00 0x137 0x01 0x00 0x136 0x01 0x00 0x19b 0x01 0x00 0x19a 0x01 0x00 0x28 0x01 0x00 0x27 0x01 0x00 0x12e 0x01 0x00 0x12d 0x01 0x00 0x25 0x01 0x00 0x24 0x01 0x00 0x128 0x01 0x00 0x127 0x01 0x00 0x126 0x01 0x00 0x125 0x01 0x00 0x124 0x01 0x00 0x123 0x01 0x00 0x122 0x01 0x00 0x121 0x01 0x00 0x120 0x01 0x00 0xef 0x01 0x00 0xec 0x01 0x00 0xeb 0x01 0x00 0xea 0x01 0x00 0xe9 0x01 0x00 0xe8 0x01 0x00 0xe7 0x01 0x00 0xe6 0x01 0x00 0xe5 0x01 0x00 0xe4 0x01 0x00 0xe0 0x01 0x00 0xdf 0x01 0x00 0xcb 0x01 0x00 0xb7 0x01 0x00 0xb4 0x01 0x00 0xb3 0x01 0x00 0xb2 0x01 0x00 0xb1 0x01 0x00 0xb0 0x01 0x00 0xa3 0x01 0x00 0xa2 0x01 0x00 0xa0 0x01 0x00 0x9f 0x01 0x00 0x9e 0x01 0x00 0x9d 0x01 0x00 0x9c 0x01>;
			compatible = "qcom,cnss-qca8074";
			qcom,board_id = <0x90>;
			qcom,hw-mode-id = <0x01>;
			qcom,bdf-addr = "K\f\0\0K\f\0\0K\f\0";
		};

		phy@8e000 {
			reset-names = "phy\0phy_phy";
			resets = <0x0b 0x52 0x0b 0x53>;
			phandle = <0x30>;
			clocks = <0x0b 0xa9>;
			reg = <0x8e000 0x1000>;
			#phy-cells = <0x00>;
			compatible = "qca,pcie-qmp-phy";
			clock-names = "pipe_clk";
			linux,phandle = <0x30>;
		};

		dp2 {
			qcom,link-poll = <0x01>;
			qcom,mactype = <0x00>;
			local-mac-address = [00 00 00 00 00 00];
			phy-mode = "sgmii";
			reg = <0x3a001200 0x200>;
			device_type = "network";
			compatible = "qcom,nss-dp";
			qcom,id = <0x02>;
			qcom,phy-mdio-addr = <0x01>;
		};

		cti@601f000 {
			clocks = <0x0b 0xee 0x0b 0xed>;
			reg = <0x601f000 0x1000>;
			reg-names = "cti-base";
			coresight-name = "coresight-cti15";
			compatible = "arm,coresight-cti";
			clock-names = "core_clk\0core_a_clk";
		};

		qcom,ipc_router {
			qcom,node-id = <0x01>;
			compatible = "qcom,ipc_router";
		};

		crypto@73a000 {
			dma-names = "rx\0tx";
			clocks = <0x0b 0x67 0x0b 0x68 0x0b 0x69>;
			dmas = <0x23 0x02 0x23 0x03>;
			reg = <0x73a000 0x6000>;
			status = "ok";
			compatible = "qcom,crypto-v5.1";
			clock-names = "iface\0bus\0core";
		};

		rpm_etm0 {
			qcom,inst-id = <0x04>;
			coresight-name = "coresight-rpm-etm0";
			compatible = "qcom,coresight-remote-etm";

			port {

				endpoint {
					phandle = <0x41>;
					remote-endpoint = <0x54>;
					linux,phandle = <0x41>;
				};
			};
		};

		dp5 {
			qcom,link-poll = <0x01>;
			qcom,mactype = <0x00>;
			local-mac-address = [00 00 00 00 00 00];
			phy-mode = "sgmii";
			reg = <0x3a001800 0x200>;
			device_type = "network";
			compatible = "qcom,nss-dp";
			qcom,id = <0x05>;
			qcom,phy-mdio-addr = <0x04>;
		};

		qrng@e1000 {
			clocks = <0x0b 0xaa>;
			reg = <0xe3000 0x1000>;
			status = "ok";
			compatible = "qcom,prng-ipq807x";
			clock-names = "core";
		};

		cti@6010000 {
			phandle = <0x34>;
			clocks = <0x0b 0xee 0x0b 0xed>;
			reg = <0x6010000 0x1000>;
			reg-names = "cti-base";
			coresight-name = "coresight-cti0";
			compatible = "arm,coresight-cti";
			clock-names = "core_clk\0core_a_clk";
			linux,phandle = <0x34>;
		};

		qcom,smem@4AB00000 {
			hwlocks = <0x1a 0x00>;
			memory-region = <0x19>;
			compatible = "qcom,smem";
		};

		nss@40800000 {
			qcom,num-irq = <0x0a>;
			qcom,clmap-enabled;
			qcom,num-queue = <0x04>;
			clocks = <0x0b 0x77 0x0b 0x88 0x0b 0x73 0x0b 0x71 0x0b 0x76 0x0b 0x8e 0x0b 0x6a 0x0b 0xd9 0x0b 0x8f 0x0b 0x70 0x0b 0x6f 0x0b 0x8a 0x0b 0x89 0x0b 0x91 0x0b 0x9e 0x0b 0x9c 0x0b 0x9d 0x0b 0x9f 0x0b 0xdb>;
			qcom,pvxlan-enabled;
			qcom,crypto-enabled;
			reg = <0x39400000 0x1000 0x38030000 0x30000 0xb111000 0x1000>;
			qcom,num-pri = <0x04>;
			qcom,tls-enabled;
			reg-names = "nphys\0vphys\0qgic-phys";
			qcom,load-addr = <0x40800000>;
			qcom,ipsec-enabled;
			qcom,rmnet_rx-enabled;
			interrupts = <0x00 0x186 0x01 0x00 0x187 0x01 0x00 0x188 0x01 0x00 0x189 0x01 0x00 0x18a 0x01 0x00 0x18b 0x01 0x00 0x18c 0x01 0x00 0x18d 0x01 0x00 0x18e 0x01 0x00 0x18f 0x01>;
			compatible = "qcom,nss";
			clock-names = "nss-noc-clk\0nss-ptp-ref-clk\0nss-csr-clk\0nss-cfg-clk\0nss-imem-clk\0nss-nssnoc-qosgen-ref-clk\0nss-mem-noc-nss-axi-clk\0nss-nssnoc-snoc-clk\0nss-nssnoc-timeout-ref-clk\0nss-ce-axi-clk\0nss-ce-apb-clk\0nss-nssnoc-ce-axi-clk\0nss-nssnoc-ce-apb-clk\0nss-nssnoc-ahb-clk\0nss-core-clk\0nss-ahb-clk\0nss-axi-clk\0nss-mpt-clk\0nss-nc-axi-clk";
			qcom,id = <0x01>;
			qcom,qvpn-enabled;
			qcom,capwap-enabled;
			qcom,dtls-enabled;
		};

		etm@619c000 {
			cpu = <0x4c>;
			clocks = <0x0b 0xee 0x0b 0xed>;
			reg = <0x619c000 0x1000>;
			coresight-name = "coresight-etm0";
			compatible = "arm,primecell";
			clock-names = "apb_pclk\0core_a_clk";
			arm,primecell-periphid = <0x3b95d>;

			port {

				endpoint {
					phandle = <0x48>;
					remote-endpoint = <0x4d>;
					linux,phandle = <0x48>;
				};
			};
		};

		dp6 {
			qcom,link-poll = <0x01>;
			qcom,mactype = <0x01>;
			local-mac-address = [00 00 00 00 00 00];
			phy-mode = "sgmii";
			reg = <0x3a007000 0x3fff>;
			device_type = "network";
			compatible = "qcom,nss-dp";
			qcom,id = <0x06>;
			qcom,phy-mdio-addr = <0x07>;
		};

		cti@601c000 {
			clocks = <0x0b 0xee 0x0b 0xed>;
			reg = <0x601c000 0x1000>;
			reg-names = "cti-base";
			coresight-name = "coresight-cti12";
			compatible = "arm,coresight-cti";
			clock-names = "core_clk\0core_a_clk";
		};

		smp2p-wcss {
			interrupt-parent = <0x01>;
			interrupts = <0x00 0x142 0x01>;
			compatible = "qcom,smp2p";
			qcom,smem = <0x1b3 0x1ac>;
			qcom,ipc = <0x18 0x08 0x09>;
			qcom,local-pid = <0x00>;
			qcom,remote-pid = <0x01>;

			slave-kernel {
				phandle = <0x12>;
				qcom,entry-name = "slave-kernel";
				#interrupt-cells = <0x02>;
				interrupt-controller;
				linux,phandle = <0x12>;
			};

			master-kernel {
				phandle = <0x13>;
				qcom,entry-name = "master-kernel";
				#qcom,smem-state-cells = <0x01>;
				qcom,smp2p-feature-ssr-ack;
				linux,phandle = <0x13>;
			};
		};

		qcom,nss_crypto {
			qcom,max-contexts = <0x40>;
			ranges;
			#address-cells = <0x01>;
			status = "ok";
			compatible = "qcom,nss-crypto";
			#size-cells = <0x01>;
			qcom,max-context-size = <0x20>;

			eip197_node {
				qcom,aes128-ctr-md5-hmac;
				qcom,aes192-ecb;
				qcom,aes256-cbc-sha256-hmac;
				qcom,aes128-cbc;
				qcom,aes128-cbc-md5-hmac;
				qcom,aes128-ctr-sha384-hmac;
				qcom,aes256-cbc-sha384-hmac;
				qcom,aes128-cbc-sha256-hmac;
				qcom,sha384-hash;
				qcom,aes256-ctr-sha256-hmac;
				qcom,md5-hmac;
				qcom,transform-enabled;
				qcom,aes256-cbc-sha160-hmac;
				qcom,sha160-hmac;
				qcom,aes128-ecb;
				qcom,aes256-ctr-md5-hmac;
				qcom,aes256-cbc-sha512-hmac;
				qcom,sha224-hmac;
				clocks = <0x0b 0x72 0x0b 0x8b 0x0b 0x6e>;
				qcom,aes192-ctr-sha384-hmac;
				qcom,aes192-ctr-sha512-hmac;
				qcom,md5-hash;
				qcom,sha512-hmac;
				qcom,aes256-ctr-sha512-hmac;
				qcom,aes128-cbc-sha512-hmac;
				qcom,aes192-cbc-sha160-hmac;
				qcom,3des-cbc-sha160-hmac;
				qcom,3des-cbc-md5-hmac;
				qcom,sha256-hash;
				reg = <0x39800000 0x7ffff>;
				qcom,aes256-cbc-md5-hmac;
				qcom,aes192-cbc-md5-hmac;
				qcom,aes192-cbc-sha512-hmac;
				qcom,sha160-hash;
				qcom,aes192-cbc;
				qcom,aes128-ctr;
				qcom,aes128-ctr-sha512-hmac;
				reg-names = "crypto_pbase";
				qcom,aes256-ctr-sha384-hmac;
				qcom,aes128-gcm-gmac;
				qcom,aes128-ctr-sha256-hmac;
				qcom,aes256-gcm-gmac;
				compatible = "qcom,eip197";
				qcom,aes256-ecb;
				qcom,dma-mask = <0xff>;
				clock-names = "crypto_clk\0crypto_nocclk\0crypto_ppeclk";
				qcom,aes192-gcm-gmac;
				qcom,aes192-cbc-sha256-hmac;
				qcom,aes192-ctr-md5-hmac;
				qcom,aes192-ctr-sha256-hmac;
				qcom,sha384-hmac;
				qcom,aes256-cbc;
				qcom,sha512-hash;
				qcom,aes192-cbc-sha384-hmac;
				qcom,sha256-hmac;
				qcom,aes192-ctr;
				qcom,aes256-ctr;
				qcom,3des-cbc-sha256-hmac;
				qcom,aes256-ctr-sha160-hmac;
				qcom,aes128-cbc-sha384-hmac;
				qcom,3des-cbc;
				qcom,aes128-cbc-sha160-hmac;
				qcom,aes192-ctr-sha160-hmac;
				qcom,aes128-ctr-sha160-hmac;
				qcom,sha224-hash;
				clock-frequency = <0x00 0x23c34600 0x00 0x23c34600 0x00 0x11e1a300>;

				engine0 {
					qcom,ifpp-enabled;
					qcom,ipue-enabled;
					qcom,opue-enabled;
					qcom,ofpp-enabled;
					reg_offset = <0x80000>;
				};
			};
		};

		syscon@b111000 {
			phandle = <0x18>;
			reg = <0xb111000 0x1000>;
			compatible = "syscon";
			linux,phandle = <0x18>;
		};

		cti@601e000 {
			clocks = <0x0b 0xee 0x0b 0xed>;
			reg = <0x601e000 0x1000>;
			reg-names = "cti-base";
			coresight-name = "coresight-cti14";
			compatible = "arm,coresight-cti";
			clock-names = "core_clk\0core_a_clk";
		};

		timer {
			always-on;
			interrupts = <0x01 0x02 0xff08 0x01 0x03 0xff08 0x01 0x04 0xff08 0x01 0x01 0xff08>;
			compatible = "arm,armv8-timer";
			clock-frequency = <0x124f800>;
		};

		clock-controller@b1b8000 {
			phandle = <0x0a>;
			reg = <0xb1b8000 0x1000>;
			compatible = "qcom,arm-cortex-acc";
			linux,phandle = <0x0a>;
		};

		serial@78af000 {
			clocks = <0x0b 0x61 0x0b 0x54>;
			reg = <0x78af000 0x200>;
			status = "disabled";
			interrupts = <0x00 0x6b 0x00>;
			compatible = "qcom,msm-uartdm-v1.4\0qcom,msm-uartdm";
			clock-names = "core\0iface";
		};

		qcom,glink-smem-native-xprt-modem@4AB00000 {
			qcom,irq-mask = <0x100>;
			reg = <0x4ab00000 0x100000 0xb111008 0x04>;
			reg-names = "smem\0irq-reg-base";
			interrupts = <0x00 0x141 0x01>;
			smem-entry = <0x1de 0x1df 0x1e0>;
			compatible = "qcom,glink-smem-native-xprt";
			qcom,subsys-id = <0x01>;
			smem-entry-names = "ch\0tx_fifo\0rx_fifo";
			label = "mpss";
		};

		funnel@61a1000 {
			clocks = <0x0b 0xee 0x0b 0xed>;
			reg = <0x61a1000 0x1000>;
			reg-names = "funnel-base";
			coresight-name = "coresight-funnel-apss0";
			compatible = "arm,primecell";
			clock-names = "apb_pclk\0core_a_clk";
			arm,primecell-periphid = <0x3b908>;

			ports {
				#address-cells = <0x01>;
				#size-cells = <0x00>;

				port@3 {
					reg = <0x02>;

					endpoint {
						phandle = <0x51>;
						slave-mode;
						remote-endpoint = <0x4a>;
						linux,phandle = <0x51>;
					};
				};

				port@0 {
					reg = <0x00>;

					endpoint {
						phandle = <0x45>;
						remote-endpoint = <0x47>;
						linux,phandle = <0x45>;
					};
				};

				port@1 {
					reg = <0x00>;

					endpoint {
						phandle = <0x4d>;
						slave-mode;
						remote-endpoint = <0x48>;
						linux,phandle = <0x4d>;
					};
				};

				port@4 {
					reg = <0x03>;

					endpoint {
						phandle = <0x53>;
						slave-mode;
						remote-endpoint = <0x4b>;
						linux,phandle = <0x53>;
					};
				};

				port@2 {
					reg = <0x01>;

					endpoint {
						phandle = <0x4f>;
						slave-mode;
						remote-endpoint = <0x49>;
						linux,phandle = <0x4f>;
					};
				};
			};
		};

		cti@6012000 {
			clocks = <0x0b 0xee 0x0b 0xed>;
			reg = <0x6012000 0x1000>;
			reg-names = "cti-base";
			coresight-name = "coresight-cti2";
			compatible = "arm,coresight-cti";
			clock-names = "core_clk\0core_a_clk";
		};

		tmc@6028000 {
			arm,buffer-size = <0x100000>;
			arm,sg-enable;
			coresight-ctis = <0x34 0x35>;
			clocks = <0x0b 0xee 0x0b 0xed>;
			memory_region = <0x11>;
			reg = <0x6028000 0x1000 0x6044000 0x15000>;
			reg-names = "tmc-base\0bam-base";
			interrupt-names = "byte-cntr-irq";
			coresight-name = "coresight-tmc-etr";
			interrupts = <0x00 0xa6 0x00>;
			compatible = "arm,primecell";
			clock-names = "apb_pclk\0core_a_clk";
			arm,primecell-periphid = <0x3b961>;

			port {

				endpoint {
					phandle = <0x37>;
					slave-mode;
					remote-endpoint = <0x36>;
					linux,phandle = <0x37>;
				};
			};
		};

		qcom,rpm-glink {
			status = "ok";
			qcom,rpm-channel-type = <0x0f>;
			compatible = "qcom,rpm-glink";
			qcom,glink-edge = "rpm";
			rpm-channel-name = "rpm_requests";

			rpm-regulator-ldoa2 {
				qcom,regulator-type = <0x00>;
				status = "disabled";
				qcom,hpm-min-load = <0x2710>;
				compatible = "qcom,rpm-glink-regulator-resource";
				qcom,resource-id = <0x02>;
				qcom,resource-name = "ldoa";

				regulator-l2 {
					status = "disabled";
					regulator-name = "ipq807x_l2";
					compatible = "qcom,rpm-glink-regulator";
					qcom,set = <0x03>;
				};
			};

			rpm-regulator-ldoa3 {
				qcom,regulator-type = <0x00>;
				status = "disabled";
				qcom,hpm-min-load = <0x2710>;
				compatible = "qcom,rpm-glink-regulator-resource";
				qcom,resource-id = <0x03>;
				qcom,resource-name = "ldoa";

				regulator-l3 {
					status = "disabled";
					regulator-name = "ipq807x_l3";
					compatible = "qcom,rpm-glink-regulator";
					qcom,set = <0x03>;
				};
			};

			rpm-regulator-smpa3 {
				qcom,regulator-type = <0x01>;
				status = "disabled";
				qcom,hpm-min-load = <0x186a0>;
				compatible = "qcom,rpm-glink-regulator-resource";
				qcom,resource-id = <0x03>;
				qcom,resource-name = "smpa";

				regulator-s3 {
					status = "disabled";
					regulator-min-microvolt = <0x90880>;
					regulator-name = "ipq807x_s3";
					compatible = "qcom,rpm-glink-regulator";
					regulator-max-microvolt = <0x103c40>;
					qcom,set = <0x03>;
				};
			};

			rpm-regulator-smpa1 {
				qcom,regulator-type = <0x01>;
				status = "disabled";
				qcom,hpm-min-load = <0x186a0>;
				compatible = "qcom,rpm-glink-regulator-resource";
				qcom,resource-id = <0x01>;
				qcom,resource-name = "smpa";

				regulator-s1 {
					status = "disabled";
					regulator-min-microvolt = <0xa3930>;
					regulator-name = "ipq807x_s1";
					compatible = "qcom,rpm-glink-regulator";
					regulator-max-microvolt = <0xf1b30>;
					qcom,always-send-voltage;
					qcom,set = <0x03>;
				};
			};

			rpm-regulator-ldoa11 {
				qcom,regulator-type = <0x00>;
				status = "disabled";
				qcom,hpm-min-load = <0x2710>;
				compatible = "qcom,rpm-glink-regulator-resource";
				qcom,resource-id = <0x0b>;
				qcom,resource-name = "ldoa";

				regulator-l11 {
					status = "disabled";
					regulator-min-microvolt = <0x10d880>;
					regulator-name = "ipq807x_l11";
					compatible = "qcom,rpm-glink-regulator";
					regulator-max-microvolt = <0x325aa0>;
					qcom,set = <0x03>;
				};
			};

			rpm-regulator-ldoa8 {
				qcom,regulator-type = <0x00>;
				status = "disabled";
				qcom,hpm-min-load = <0x1388>;
				compatible = "qcom,rpm-glink-regulator-resource";
				qcom,resource-id = <0x08>;
				qcom,resource-name = "ldoa";

				regulator-l8 {
					status = "disabled";
					regulator-name = "ipq807x_l8";
					compatible = "qcom,rpm-glink-regulator";
					qcom,set = <0x03>;
				};
			};

			rpm-regulator-ldoa12 {
				qcom,regulator-type = <0x00>;
				status = "disabled";
				qcom,hpm-min-load = <0x2710>;
				compatible = "qcom,rpm-glink-regulator-resource";
				qcom,resource-id = <0x0c>;
				qcom,resource-name = "ldoa";

				regulator-l12 {
					status = "disabled";
					regulator-name = "ipq807x_l12";
					compatible = "qcom,rpm-glink-regulator";
					qcom,set = <0x03>;
				};
			};

			rpm-regulator-ldoa10 {
				qcom,regulator-type = <0x00>;
				status = "disabled";
				qcom,hpm-min-load = <0x2710>;
				compatible = "qcom,rpm-glink-regulator-resource";
				qcom,resource-id = <0x0a>;
				qcom,resource-name = "ldoa";

				regulator-l10 {
					status = "disabled";
					regulator-name = "ipq807x_l10";
					compatible = "qcom,rpm-glink-regulator";
					qcom,set = <0x03>;
				};
			};

			rpm-regulator-ldoa13 {
				qcom,regulator-type = <0x00>;
				status = "disabled";
				qcom,hpm-min-load = <0x2710>;
				compatible = "qcom,rpm-smd-regulator-resource";
				qcom,resource-id = <0x0d>;
				qcom,resource-name = "ldoa";

				regulator-l13 {
					status = "disabled";
					regulator-name = "ipq807x_l13";
					compatible = "qcom,rpm-glink-regulator";
					qcom,set = <0x03>;
				};
			};

			rpm-regulator-ldoa4 {
				qcom,regulator-type = <0x00>;
				status = "disabled";
				qcom,hpm-min-load = <0x2710>;
				compatible = "qcom,rpm-glink-regulator-resource";
				qcom,resource-id = <0x04>;
				qcom,resource-name = "ldoa";

				regulator-l4 {
					status = "disabled";
					regulator-name = "ipq807x_l4";
					compatible = "qcom,rpm-glink-regulator";
					qcom,set = <0x03>;
				};
			};

			rpm-regulator-ldoa6 {
				qcom,regulator-type = <0x00>;
				status = "disabled";
				qcom,hpm-min-load = <0x2710>;
				compatible = "qcom,rpm-glink-regulator-resource";
				qcom,resource-id = <0x06>;
				qcom,resource-name = "ldoa";

				regulator-l6 {
					status = "disabled";
					regulator-name = "ipq807x_l6";
					compatible = "qcom,rpm-glink-regulator";
					qcom,set = <0x03>;
				};
			};

			rpm-regulator-ldoa9 {
				qcom,regulator-type = <0x00>;
				status = "disabled";
				qcom,hpm-min-load = <0x2710>;
				compatible = "qcom,rpm-glink-regulator-resource";
				qcom,resource-id = <0x09>;
				qcom,resource-name = "ldoa";

				regulator-l9 {
					status = "disabled";
					regulator-name = "ipq807x_l9";
					compatible = "qcom,rpm-glink-regulator";
					qcom,set = <0x03>;
				};
			};

			rpm-regulator-ldoa1 {
				qcom,regulator-type = <0x00>;
				status = "disabled";
				qcom,hpm-min-load = <0x2710>;
				compatible = "qcom,rpm-glink-regulator-resource";
				qcom,resource-id = <0x01>;
				qcom,resource-name = "ldoa";

				regulator-l1 {
					status = "disabled";
					regulator-name = "ipq807x_l1";
					compatible = "qcom,rpm-glink-regulator";
					qcom,set = <0x03>;
				};
			};

			rpm-regulator-smpa5 {
				qcom,regulator-type = <0x01>;
				status = "disabled";
				qcom,hpm-min-load = <0x186a0>;
				compatible = "qcom,rpm-glink-regulator-resource";
				qcom,resource-id = <0x05>;
				qcom,resource-name = "smpa";

				regulator-s5 {
					phandle = <0x21>;
					status = "disabled";
					regulator-min-microvolt = <0x00>;
					regulator-name = "ipq807x_s5";
					compatible = "qcom,rpm-glink-regulator";
					regulator-max-microvolt = <0x09>;
					linux,phandle = <0x21>;
					qcom,set = <0x01>;
					qcom,use-voltage-corner;
				};
			};

			rpm-regulator-smpa2 {
				qcom,regulator-type = <0x01>;
				status = "disabled";
				qcom,hpm-min-load = <0x186a0>;
				compatible = "qcom,rpm-glink-regulator-resource";
				qcom,resource-id = <0x02>;
				qcom,resource-name = "smpa";

				regulator-s2 {
					status = "disabled";
					regulator-name = "ipq807x_s2";
					compatible = "qcom,rpm-glink-regulator";
					qcom,set = <0x03>;
				};
			};

			rpm-regulator-ldoa5 {
				qcom,regulator-type = <0x00>;
				status = "disabled";
				qcom,hpm-min-load = <0x2710>;
				compatible = "qcom,rpm-glink-regulator-resource";
				qcom,resource-id = <0x05>;
				qcom,resource-name = "ldoa";

				regulator-l5 {
					status = "disabled";
					regulator-name = "ipq807x_l5";
					compatible = "qcom,rpm-glink-regulator";
					qcom,set = <0x03>;
				};
			};

			rpm-regulator-smpa4 {
				qcom,regulator-type = <0x01>;
				status = "disabled";
				qcom,hpm-min-load = <0x186a0>;
				compatible = "qcom,rpm-glink-regulator-resource";
				qcom,resource-id = <0x04>;
				qcom,resource-name = "smpa";

				regulator-s4 {
					status = "disabled";
					regulator-min-microvolt = <0xadd40>;
					regulator-name = "ipq807x_s4";
					compatible = "qcom,rpm-glink-regulator";
					regulator-max-microvolt = <0xf2300>;
					qcom,set = <0x03>;
				};
			};

			rpm-regulator-ldoa7 {
				qcom,regulator-type = <0x00>;
				status = "disabled";
				qcom,hpm-min-load = <0x2710>;
				compatible = "qcom,rpm-glink-regulator-resource";
				qcom,resource-id = <0x07>;
				qcom,resource-name = "ldoa";

				regulator-l7 {
					status = "disabled";
					regulator-name = "ipq807x_l7";
					compatible = "qcom,rpm-glink-regulator";
					qcom,set = <0x03>;
				};
			};
		};

		thermal-sensor@4a8000 {
			#thermal-sensor-cells = <0x01>;
			phandle = <0x5f>;
			reg = <0x4a8000 0x2000>;
			status = "ok";
			interrupts = <0x00 0xb8 0x00>;
			compatible = "qcom,ipq807x-tsens";
			linux,phandle = <0x5f>;
			tsens-up-low-int-clr-deassert-quirk;
		};

		gpio-ctrl {
			HWID2 = <0x1d 0x03 0x00>;
			pinctrl-0 = <0x5d>;
			FAN_EN = <0x1d 0x08 0x00>;
			pinctrl-names = "default";
			status = "ok";
			compatible = "qcom,gpio-ctrl";
			HWID0 = <0x1d 0x06 0x00>;
			HWID1 = <0x1d 0x04 0x00>;
		};

		qcom,msm-imem@8600000 {
			ranges = <0x00 0x8600000 0x1000>;
			#address-cells = <0x01>;
			reg = <0x8600000 0x1000>;
			status = "disabled";
			compatible = "qcom,msm-imem";
			#size-cells = <0x01>;

			mem_dump_table@10 {
				reg = <0x10 0x08>;
				compatible = "qcom,msm-imem-mem_dump_table";
			};
		};

		qcom,usbbam@8B04000 {
			qcom,bam-type = <0x00>;
			qcom,reset-bam-on-connect;
			qcom,usb-bam-fifo-baseaddr = "J`\0";
			qcom,ignore-core-reset-ack;
			qcom,usb-bam-override-threshold = <0x4001>;
			reg = <0x8b04000 0x17000>;
			qcom,usb-bam-num-pipes = <0x04>;
			interrupt-parent = <0x01>;
			interrupts = <0x00 0x87 0x00>;
			qcom,usb-bam-max-mbps-highspeed = <0x190>;
			compatible = "qcom,usb-bam-msm";
			qcom,disable-clk-gating;
			qcom,usb-bam-max-mbps-superspeed = <0xe10>;

			qcom,pipe0 {
				qcom,dst-bam-pipe-index = <0x00>;
				qcom,peer-bam-physical-address = <0x6044000>;
				qcom,data-fifo-size = <0xe00>;
				qcom,pipe-num = <0x00>;
				qcom,peer-bam = <0x00>;
				qcom,descriptor-fifo-size = <0x200>;
				qcom,src-bam-pipe-index = <0x00>;
				qcom,usb-bam-mem-type = <0x02>;
				qcom,data-fifo-offset = <0x00>;
				qcom,dir = <0x01>;
				label = "ssusb-qdss-in-0";
				qcom,descriptor-fifo-offset = <0xe00>;
			};
		};

		dma@7884000 {
			phandle = <0x0e>;
			clocks = <0x0b 0x54>;
			qcom,ee = <0x00>;
			reg = <0x7884000 0x2b000>;
			#dma-cells = <0x01>;
			interrupts = <0x00 0xee 0x00>;
			compatible = "qcom,bam-v1.7.0";
			clock-names = "bam_clk";
			linux,phandle = <0x0e>;
		};

		serial@78B1000 {
			dma-names = "tx\0rx";
			clocks = <0x0b 0x63 0x0b 0x54>;
			dmas = <0x0e 0x04 0x0e 0x05>;
			reg = <0x78b1000 0x200>;
			status = "disabled";
			interrupts = <0x00 0x132 0x00>;
			compatible = "qcom,msm-uartdm-v1.4\0qcom,msm-uartdm";
			clock-names = "core\0iface";
		};

		hwlock@1905000 {
			phandle = <0x1a>;
			syscon = <0x1b 0x00 0x80>;
			compatible = "qcom,tcsr-mutex";
			linux,phandle = <0x1a>;
			#hwlock-cells = <0x01>;
		};

		qcom,ipc_router_modem_xprt {
			qcom,glink-xprt = "smem";
			qcom,ch-name = "IPCRTR";
			qcom,fragmented-data;
			qcom,xprt-linkid = <0x01>;
			compatible = "qcom,ipc_router_glink_xprt";
			qcom,xprt-version = <0x01>;
			qcom,xprt-remote = "mpss";
		};

		pwm {
			pinctrl-0 = <0x33>;
			used-pwm-indices = <0x01 0x00 0x00 0x00>;
			clocks = <0x0b 0xf0>;
			pinctrl-names = "default";
			status = "ok";
			compatible = "qca,ipq4019-pwm";
			clock-names = "core";
			pwm-base-index = <0x00>;
		};

		cti@6019000 {
			clocks = <0x0b 0xee 0x0b 0xed>;
			reg = <0x6019000 0x1000>;
			reg-names = "cti-base";
			coresight-name = "coresight-cti9";
			compatible = "arm,coresight-cti";
			clock-names = "core_clk\0core_a_clk";
		};

		cti@6198000 {
			cpu = <0x4c>;
			clocks = <0x0b 0xee 0x0b 0xed>;
			reg = <0x6198000 0x1000>;
			reg-names = "cti-base";
			coresight-name = "coresight-cti-cpu0";
			compatible = "arm,coresight-cti";
			clock-names = "core_clk\0core_a_clk";
		};

		cti@6199000 {
			cpu = <0x4e>;
			clocks = <0x0b 0xee 0x0b 0xed>;
			reg = <0x6199000 0x1000>;
			reg-names = "cti-base";
			coresight-name = "coresight-cti-cpu1";
			compatible = "arm,coresight-cti";
			clock-names = "core_clk\0core_a_clk";
		};

		dma@7984000 {
			phandle = <0x24>;
			clocks = <0x0b 0xab>;
			qcom,ee = <0x00>;
			reg = <0x7984000 0x1a000>;
			#dma-cells = <0x01>;
			status = "ok";
			interrupts = <0x00 0x92 0x00>;
			compatible = "qcom,bam-v1.7.0";
			clock-names = "bam_clk";
			linux,phandle = <0x24>;
		};

		tpdm@6110000 {
			clocks = <0x0b 0xee 0x0b 0xed>;
			reg = <0x6110000 0x1000>;
			reg-names = "tpdm-base";
			coresight-name = "coresight-tpdm-dcc";
			compatible = "qcom,coresight-tpdm";
			clock-names = "core_clk\0core_a_clk";

			port {

				endpoint {
					phandle = <0x58>;
					remote-endpoint = <0x59>;
					linux,phandle = <0x58>;
				};
			};
		};

		q6v5_m3 {
			phandle = <0x14>;
			compatible = "qca,q6v5-m3-rproc";
			qca,auto-restart;
			linux,phandle = <0x14>;
			qcom,restart-group = <0x14 0x15>;
			firmware = "IPQ8074/m3_fw.mdt";
		};

		qcom,glink-ssr-modem {
			qcom,edge = "mpss";
			compatible = "qcom,glink_ssr";
			qca,no-notify-edges;
			label = "q6v5-wcss";
			qcom,xprt = "smem";
		};

		apm@b111000 {
			qcom,apm-halt-clk-delay = <0x11>;
			qcom,apm-post-halt-delay = <0x02>;
			phandle = <0x5a>;
			reg = <0xb111000 0x1000>;
			reg-names = "pm-apcc-glb";
			compatible = "qcom,ipq807x-apm";
			qcom,apm-sel-switch-delay = <0x01>;
			linux,phandle = <0x5a>;
			qcom,apm-resume-clk-delay = <0x10>;
		};

		qcom,rpm-log@29fc00 {
			qcom,offset-log-len-mask = <0x2c>;
			qcom,offset-page-indices = <0x38>;
			qcom,offset-version = <0x04>;
			reg = <0x29fc00 0x4000>;
			qcom,rpm-addr-phys = <0x200000>;
			compatible = "qcom,rpm-log";
			qcom,offset-log-len = <0x28>;
			qcom,offset-page-buffer-addr = <0x24>;
		};

		qca,scm_restart_reason {
			dload_warm_reset = <0x00>;
			dload_status = <0x00>;
			compatible = "qca,scm_restart_reason";
		};

		qcom,apss_clk@b111000 {
			phandle = <0x02>;
			#clock-cells = <0x01>;
			reg = <0xb111000 0x6000>;
			compatible = "qcom,apss-ipq807x";
			#reset-cells = <0x01>;
			linux,phandle = <0x02>;
		};

		qusb@79000 {
			reset-names = "usb2_phy_reset";
			resets = <0x0b 0x2f>;
			phandle = <0x26>;
			phy_type = "utmi";
			reg = <0x79000 0x180 0x8af8800 0x400 0x1841030 0x04>;
			status = "ok";
			reg-names = "qusb_phy_base\0qscratch_base\0ref_clk_addr";
			qcom,qusb-phy-init-seq = <0xf8 0x80 0x83 0x84 0x83 0x88 0xc0 0x8c 0x30 0x08 0x79 0x0c 0x21 0x10 0x14 0x9c 0x80 0x04 0x9f 0x1c>;
			compatible = "qcom,qusb2phy";
			linux,phandle = <0x26>;
		};

		etm@619f000 {
			cpu = <0x52>;
			clocks = <0x0b 0xee 0x0b 0xed>;
			reg = <0x619f000 0x1000>;
			coresight-name = "coresight-etm3";
			compatible = "arm,primecell";
			clock-names = "apb_pclk\0core_a_clk";
			arm,primecell-periphid = <0x3b95d>;

			port {

				endpoint {
					phandle = <0x4b>;
					remote-endpoint = <0x53>;
					linux,phandle = <0x4b>;
				};
			};
		};

		watchdog@b017000 {
			wdt-max-timeout = <0x20>;
			clocks = <0x22>;
			mhi-wdt-panic-enable;
			reg = <0xb017000 0x1000>;
			timeout-sec = <0x0a>;
			reg-names = "kpss_wdt";
			interrupt-names = "bark_irq";
			interrupts = <0x00 0x03 0x00>;
			compatible = "qcom,kpss-wdt-ipq807x";
		};

		qcom,glink-rpm-native-xprt@60000 {
			qcom,irq-mask = <0x01>;
			reg = <0x60000 0x6000 0xb111008 0x04>;
			status = "disabled";
			reg-names = "msgram\0irq-reg-base";
			interrupts = <0x00 0xa8 0x01>;
			compatible = "qcom,glink-rpm-native-xprt";
			qcom,subsys-id = <0x06>;
			label = "rpm";
		};

		wifi1@c0000000 {
			qcom,rproc = <0x31>;
			qcom,bt-priority-time = <0x0c>;
			qcom,bt-active-time = <0x12>;
			reg = <0xc000000 0x2000000>;
			qcom,caldb-size = <0x480000>;
			status = "ok";
			qcom,tgt-mem-mode = <0x00>;
			interrupt-names = "misc-pulse1\0misc-latch\0sw-exception\0watchdog\0ce0\0ce1\0ce2\0ce3\0ce4\0ce5\0ce6\0ce7\0ce8\0ce9\0ce10\0ce11\0host2wbm-desc-feed\0host2reo-re-injection\0host2reo-command\0host2rxdma-monitor-ring3\0host2rxdma-monitor-ring2\0host2rxdma-monitor-ring1\0reo2ost-exception\0wbm2host-rx-release\0reo2host-status\0reo2host-destination-ring4\0reo2host-destination-ring3\0reo2host-destination-ring2\0reo2host-destination-ring1\0rxdma2host-monitor-destination-mac3\0rxdma2host-monitor-destination-mac2\0rxdma2host-monitor-destination-mac1\0ppdu-end-interrupts-mac3\0ppdu-end-interrupts-mac2\0ppdu-end-interrupts-mac1\0rxdma2host-monitor-status-ring-mac3\0rxdma2host-monitor-status-ring-mac2\0rxdma2host-monitor-status-ring-mac1\0host2rxdma-host-buf-ring-mac3\0host2rxdma-host-buf-ring-mac2\0host2rxdma-host-buf-ring-mac1\0rxdma2host-destination-ring-mac3\0rxdma2host-destination-ring-mac2\0rxdma2host-destination-ring-mac1\0host2tcl-input-ring4\0host2tcl-input-ring3\0host2tcl-input-ring2\0host2tcl-input-ring1\0wbm2host-tx-completions-ring3\0wbm2host-tx-completions-ring2\0wbm2host-tx-completions-ring1\0tcl2host-status-ring";
			qcom,caldb-addr = <0x4ba00000 0x4ba00000 0x00>;
			interrupts = <0x00 0x140 0x01 0x00 0x13f 0x01 0x00 0x13e 0x01 0x00 0x13d 0x01 0x00 0x13c 0x01 0x00 0x13b 0x01 0x00 0x13a 0x01 0x00 0x137 0x01 0x00 0x136 0x01 0x00 0x19b 0x01 0x00 0x19a 0x01 0x00 0x28 0x01 0x00 0x27 0x01 0x00 0x12e 0x01 0x00 0x12d 0x01 0x00 0x25 0x01 0x00 0x24 0x01 0x00 0x128 0x01 0x00 0x127 0x01 0x00 0x126 0x01 0x00 0x125 0x01 0x00 0x124 0x01 0x00 0x123 0x01 0x00 0x122 0x01 0x00 0x121 0x01 0x00 0x120 0x01 0x00 0xef 0x01 0x00 0xec 0x01 0x00 0xeb 0x01 0x00 0xea 0x01 0x00 0xe9 0x01 0x00 0xe8 0x01 0x00 0xe7 0x01 0x00 0xe6 0x01 0x00 0xe5 0x01 0x00 0xe4 0x01 0x00 0xe0 0x01 0x00 0xdf 0x01 0x00 0xcb 0x01 0x00 0xb7 0x01 0x00 0xb4 0x01 0x00 0xb3 0x01 0x00 0xb2 0x01 0x00 0xb1 0x01 0x00 0xb0 0x01 0x00 0xa3 0x01 0x00 0xa2 0x01 0x00 0xa0 0x01 0x00 0x9f 0x01 0x00 0x9e 0x01 0x00 0x9d 0x01 0x00 0x9c 0x01>;
			qcom,pta-num = <0x00>;
			compatible = "qcom,cnss-qca8074v2\0qcom,ipq8074-wifi";
			qcom,board_id = <0x290>;
			qcom,pta-priority = <0x80800505>;
			qcom,hw-mode-id = <0x01>;
			qcom,bdf-addr = "K\f\0\0K\f\0\0K\f\0";
			qcom,coex-algo = <0x02>;
			qcom,coex-mode = <0x02>;
		};

		hwevent@6101000 {
			clocks = <0x0b 0xee 0x0b 0xed>;
			reg = <0x6101000 0x148 0x6101fb0 0x04 0x6121000 0x148 0x6121fb0 0x04 0x6131000 0x148 0x6131fb0 0x04 0x6130fb0 0x04 0x6130000 0x148 0x6021fb0 0x04 0x6021000 0x148>;
			reg-names = "center-wrapper-mux\0center-wrapper-lockaccess\0right-wrapper-mux\0right-wrapper-lockaccess\0mm-wrapper-mux\0mm-wrapper-lockaccess\0mm-fun-lockaccess\0mm-fun\0in-fun-lockaccess\0in-fun";
			coresight-name = "coresight-hwevent";
			compatible = "qcom,coresight-hwevent";
			clock-names = "core_clk\0core_a_clk";
		};

		funnel@6130000 {
			clocks = <0x0b 0xee 0x0b 0xed>;
			reg = <0x6130000 0x1000>;
			reg-names = "funnel-base";
			coresight-name = "coresight-funnel-mm";
			compatible = "arm,primecell";
			clock-names = "apb_pclk\0core_a_clk";
			arm,primecell-periphid = <0x3b908>;

			ports {
				#address-cells = <0x01>;
				#size-cells = <0x00>;

				port@0 {
					reg = <0x00>;

					endpoint {
						phandle = <0x3e>;
						remote-endpoint = <0x46>;
						linux,phandle = <0x3e>;
					};
				};

				port@1 {
					reg = <0x06>;

					endpoint {
						slave-mode;
					};
				};
			};
		};

		etm@619e000 {
			cpu = <0x50>;
			clocks = <0x0b 0xee 0x0b 0xed>;
			reg = <0x619e000 0x1000>;
			coresight-name = "coresight-etm2";
			compatible = "arm,primecell";
			clock-names = "apb_pclk\0core_a_clk";
			arm,primecell-periphid = <0x3b95d>;

			port {

				endpoint {
					phandle = <0x4a>;
					remote-endpoint = <0x51>;
					linux,phandle = <0x4a>;
				};
			};
		};

		sdhci@7824900 {
			qcom,vdd-io-voltage-level = <0x1b7740 0x1b7740>;
			qcom,bus-speed-mode = "HS200_1p8v\0DDR_1p8v";
			qcom,nonremovable;
			qcom,bus-width = <0x08>;
			qcom,vdd-io-lpm-sup;
			qcom,msm-bus,vectors-KBps = <0x4e 0x200 0x00 0x00 0x4e 0x200 0x416 0xc80 0x4e 0x200 0xcc3e 0x27100 0x4e 0x200 0xff50 0x30d40 0x4e 0x200 0x1fe9e 0x61a80 0x4e 0x200 0x3fd3e 0xc3500 0x4e 0x200 0x3fd3e 0xc3500 0x4e 0x200 0x3fd3e 0xc3500 0x4e 0x200 0x146cc2 0x3e8000>;
			clocks = <0x0b 0xad 0x0b 0xae 0x0b 0xf2>;
			qcom,vdd-voltage-level = <0x2c4020 0x2c4020>;
			qcom,msm-bus,num-cases = <0x09>;
			reg = <0x7824900 0x500 0x7824000 0x800>;
			qcom,large-address-bus;
			syscon = <0x17 0xa000 0x19e5b>;
			status = "ok";
			qcom,vdd-io-always-on;
			qcom,vdd-io-current-level = <0xc8 0x4f588>;
			reg-names = "hc_mem\0core_mem";
			qcom,clk-rates = <0x61a80 0x17d7840 0x2faf080 0x5f5e100 0xb71b000 0x16e36000>;
			qcom,msm-bus,num-paths = <0x01>;
			qcom,max_clk = <0x16e36000>;
			interrupt-names = "hc_irq\0pwr_irq";
			interrupts = <0x00 0x7b 0x00 0x00 0x8a 0x00>;
			qcom,msm-bus,name = "sdhc1";
			qcom,cpu-dma-latency-us = <0x2bd>;
			qcom,vdd-current-level = <0xc8 0x8b290>;
			sdhc-msm-crypto = <0x16>;
			qcom,disable-aggressive-pm;
			qcom,dedicated-io = <0x01>;
			compatible = "qcom,sdhci-msm";
			clock-names = "iface_clk\0core_clk\0ice_core_clk";
			qcom,bus-bw-vectors-bps = <0x00 0x61a80 0x1312d00 0x17d7840 0x2faf080 0x5f5e100 0xbebc200 0x17d78400 0xffffffff>;
			qcom,ice-clk-rates = <0x9896800 0x12646790>;
		};

		audio@7700000 {
			reset-names = "blk_rst";
			resets = <0x0b 0x1a>;
			reg = <0x7700000 0x34>;
			compatible = "qca,ipq8074-audio-adss";
		};

		tpda@6003000 {
			clocks = <0x0b 0xee 0x0b 0xed>;
			reg = <0x6003000 0x1000>;
			reg-names = "tpda-base";
			coresight-name = "coresight-tpda";
			compatible = "qcom,coresight-tpda";
			qcom,tpda-atid = <0x40>;
			clock-names = "core_clk\0core_a_clk";
			qcom,cmb-elem-size = <0x00 0x20>;

			ports {
				#address-cells = <0x01>;
				#size-cells = <0x00>;

				port@0 {
					reg = <0x00>;

					endpoint {
						phandle = <0x3f>;
						remote-endpoint = <0x57>;
						linux,phandle = <0x3f>;
					};
				};

				port@1 {
					reg = <0x00>;

					endpoint {
						phandle = <0x59>;
						slave-mode;
						remote-endpoint = <0x58>;
						linux,phandle = <0x59>;
					};
				};
			};
		};
	};

	cpus {
		#address-cells = <0x01>;
		#size-cells = <0x00>;

		idle-states {
			entry-method = "psci";

			cpu-hotplug {
				phandle = <0x08>;
				arm,psci-suspend-param = <0x10000>;
				status = "disabled";
				local-timer-stop;
				min-residency-us = <0x7d0>;
				compatible = "arm,idle-state";
				entry-latency-us = <0x64>;
				linux,phandle = <0x08>;
				exit-latency-us = <0x2bc>;
			};
		};

		cpu@1 {
			voltage-tolerance = <0x01>;
			operating-points-v2 = <0x05>;
			phandle = <0x4e>;
			qcom,acc = <0x07>;
			clocks = <0x02 0x03>;
			reg = <0x01>;
			enable-method = "psci";
			device_type = "cpu";
			compatible = "arm,cortex-a53";
			clock-names = "cpu";
			next-level-cache = <0x04>;
			cpu-idle-states = <0x08>;
			cpu-supply = <0x06>;
			linux,phandle = <0x4e>;
		};

		cpu@0 {
			voltage-tolerance = <0x01>;
			enable-cpu-regulator;
			operating-points-v2 = <0x05>;
			phandle = <0x4c>;
			qcom,acc = <0x03>;
			clocks = <0x02 0x03>;
			reg = <0x00>;
			enable-method = "psci";
			device_type = "cpu";
			compatible = "arm,cortex-a53";
			cpu0-supply = <0x06>;
			clock-names = "cpu";
			next-level-cache = <0x04>;
			cpu-idle-states;
			linux,phandle = <0x4c>;

			l2-cache {
				phandle = <0x04>;
				compatible = "arm,arch-cache";
				linux,phandle = <0x04>;
				cache-level = <0x02>;
			};
		};

		cpu@3 {
			voltage-tolerance = <0x01>;
			operating-points-v2 = <0x05>;
			phandle = <0x52>;
			qcom,acc = <0x0a>;
			clocks = <0x02 0x03>;
			reg = <0x03>;
			enable-method = "psci";
			device_type = "cpu";
			compatible = "arm,cortex-a53";
			clock-names = "cpu";
			next-level-cache = <0x04>;
			cpu-idle-states = <0x08>;
			cpu-supply = <0x06>;
			linux,phandle = <0x52>;
		};

		opp_table0 {
			phandle = <0x05>;
			opp-shared;
			compatible = "operating-points-v2";
			linux,phandle = <0x05>;

			opp03 {
				opp-microvolt = <0x03>;
				opp-hz = <0x00 0x626b5000>;
				clock-latency-ns = <0x30d40>;
			};

			opp05 {
				opp-microvolt = <0x05>;
				opp-hz = <0x00 0x7270e000>;
				clock-latency-ns = <0x30d40>;
			};

			opp02 {
				opp-microvolt = <0x02>;
				opp-hz = <0x00 0x5265c000>;
				clock-latency-ns = <0x30d40>;
			};

			opp01 {
				opp-microvolt = <0x01>;
				opp-hz = <0x00 0x3ca75800>;
				clock-latency-ns = <0x30d40>;
			};

			opp04 {
				opp-microvolt = <0x04>;
				opp-hz = <0x00 0x6ddd0000>;
				clock-latency-ns = <0x30d40>;
			};

			opp06 {
				opp-microvolt = <0x06>;
				opp-hz = <0x00 0x839b6800>;
				clock-latency-ns = <0x30d40>;
			};

			opp00 {
				opp-microvolt = <0x00>;
				opp-hz = <0x00 0x00>;
				clock-latency-ns = <0x30d40>;
			};
		};

		cpu@2 {
			voltage-tolerance = <0x01>;
			operating-points-v2 = <0x05>;
			phandle = <0x50>;
			qcom,acc = <0x09>;
			clocks = <0x02 0x03>;
			reg = <0x02>;
			enable-method = "psci";
			device_type = "cpu";
			compatible = "arm,cortex-a53";
			clock-names = "cpu";
			next-level-cache = <0x04>;
			cpu-idle-states = <0x08>;
			cpu-supply = <0x06>;
			linux,phandle = <0x50>;
		};
	};

	memory {
		reg = <0x00 0x40000000 0x00 0x40000000>;
		device_type = "memory";
	};

	aliases {
		ethernet4 = "/soc/dp5";
		ethernet5 = "/soc/dp6";
		sdhc1 = "/soc/sdhci@7824900";
		ethernet2 = "/soc/dp3";
		ethernet0 = "/soc/dp1";
		ethernet1 = "/soc/dp2";
		ethernet3 = "/soc/dp4";
	};

	clocks {

		bias_pll_nss_noc_clk {
			#clock-cells = <0x00>;
			compatible = "fixed-clock";
			clock-frequency = <0x18d34920>;
		};

		xo {
			#clock-cells = <0x00>;
			compatible = "fixed-clock";
			clock-frequency = <0x124f800>;
		};

		usb3phy_1_cc_pipe_clk {
			#clock-cells = <0x00>;
			compatible = "fixed-clock";
			clock-frequency = <0x7735940>;
		};

		sleep_clk {
			phandle = <0x22>;
			#clock-cells = <0x00>;
			compatible = "fixed-clock";
			linux,phandle = <0x22>;
			clock-frequency = <0x7d00>;
		};

		usb3phy_0_cc_pipe_clk {
			#clock-cells = <0x00>;
			compatible = "fixed-clock";
			clock-frequency = <0x7735940>;
		};

		bias_pll_cc_clk {
			#clock-cells = <0x00>;
			compatible = "fixed-clock";
			clock-frequency = <0x11e1a300>;
		};

		pcie20_phy1_pipe_clk {
			#clock-cells = <0x00>;
			compatible = "fixed-clock";
			clock-frequency = <0x7735940>;
		};
	};

	qseecom {
		notify-align = <0x01>;
		mem-size = <0x200000>;
		mem-start = "J@\0";
		compatible = "ipq807x-qseecom";
	};

	reserved-memory {
		ranges;
		#address-cells = <0x02>;
		#size-cells = <0x02>;

		nss@40000000 {
			reg = <0x00 0x40000000 0x00 0x1000000>;
			no-map;
		};

		uboot@4a600000 {
			reg = <0x00 0x4a600000 0x00 0x400000>;
			no-map;
		};

		q6_etr_dump@50f00000 {
			phandle = <0x11>;
			reg = <0x00 0x50f00000 0x00 0x100000>;
			no-map;
			linux,phandle = <0x11>;
		};

		wigig_dump@51300000 {
			reg = <0x00 0x51300000 0x00 0x400000>;
			no-map;
		};

		m3_dump@51000000 {
			reg = <0x00 0x51000000 0x00 0x100000>;
			no-map;
		};

		tzapp@4a400000 {
			reg = <0x00 0x4a400000 0x00 0x200000>;
			no-map;
		};

		sbl@4aa00000 {
			reg = <0x00 0x4aa00000 0x00 0x100000>;
			no-map;
		};

		tz@4ac00000 {
			reg = <0x00 0x4ac00000 0x00 0x400000>;
			no-map;
		};

		wifi_dump@51100000 {
			reg = <0x00 0x51100000 0x00 0x600000>;
			no-map;
		};

		wcnss@4b000000 {
			phandle = <0x10>;
			reg = <0x00 0x4b000000 0x00 0x5f00000>;
			no-map;
			linux,phandle = <0x10>;
		};

		smem@4ab00000 {
			phandle = <0x19>;
			reg = <0x00 0x4ab00000 0x00 0x100000>;
			no-map;
			linux,phandle = <0x19>;
		};
	};

	pmu {
		interrupts = <0x01 0x07 0xf04>;
		compatible = "arm,cortex-a53-pmu";
	};

	psci {
		method = "smc";
		status = "ok";
		compatible = "arm,psci-1.0";
	};

	thermal-zones {

		tsens_tz_sensor14 {
			polling-delay-passive = <0x00>;
			thermal-sensors = <0x5f 0x0e>;
			polling-delay = <0x00>;

			trips {

				cpu-config-lo {
					type = "configurable_lo";
					temperature = <0x5f>;
					hysteresis = <0x02>;
				};

				cpu-config-hi {
					type = "configurable_hi";
					temperature = <0x69>;
					hysteresis = <0x02>;
				};

				cpu-critical-hi {
					type = "critical_high";
					temperature = <0x7d>;
					hysteresis = <0x02>;
				};

				cpu-critical-low {
					type = "critical_low";
					temperature = <0x00>;
					hysteresis = <0x02>;
				};
			};
		};

		tsens_tz_sensor13 {
			polling-delay-passive = <0x00>;
			thermal-sensors = <0x5f 0x0d>;
			polling-delay = <0x00>;

			trips {

				cpu-config-lo {
					type = "configurable_lo";
					temperature = <0x5f>;
					hysteresis = <0x02>;
				};

				cpu-config-hi {
					type = "configurable_hi";
					temperature = <0x69>;
					hysteresis = <0x02>;
				};

				cpu-critical-hi {
					type = "critical_high";
					temperature = <0x7d>;
					hysteresis = <0x02>;
				};

				cpu-critical-low {
					type = "critical_low";
					temperature = <0x00>;
					hysteresis = <0x02>;
				};
			};
		};

		tsens_tz_sensor8 {
			polling-delay-passive = <0x00>;
			thermal-sensors = <0x5f 0x08>;
			polling-delay = <0x00>;

			trips {

				cpu-config-lo {
					type = "configurable_lo";
					temperature = <0x5f>;
					hysteresis = <0x02>;
				};

				cpu-config-hi {
					type = "configurable_hi";
					temperature = <0x69>;
					hysteresis = <0x02>;
				};

				cpu-critical-hi {
					type = "critical_high";
					temperature = <0x7d>;
					hysteresis = <0x02>;
				};

				cpu-critical-low {
					type = "critical_low";
					temperature = <0x00>;
					hysteresis = <0x02>;
				};
			};
		};

		tsens_tz_sensor6 {
			polling-delay-passive = <0x00>;
			thermal-sensors = <0x5f 0x06>;
			polling-delay = <0x00>;

			trips {

				cpu-config-lo {
					type = "configurable_lo";
					temperature = <0x5f>;
					hysteresis = <0x02>;
				};

				cpu-config-hi {
					type = "configurable_hi";
					temperature = <0x69>;
					hysteresis = <0x02>;
				};

				cpu-critical-hi {
					type = "critical_high";
					temperature = <0x7d>;
					hysteresis = <0x02>;
				};

				cpu-critical-low {
					type = "critical_low";
					temperature = <0x00>;
					hysteresis = <0x02>;
				};
			};
		};

		tsens_tz_sensor4 {
			polling-delay-passive = <0x00>;
			thermal-sensors = <0x5f 0x04>;
			polling-delay = <0x00>;

			trips {

				cpu-config-lo {
					type = "configurable_lo";
					temperature = <0x5f>;
					hysteresis = <0x02>;
				};

				cpu-config-hi {
					type = "configurable_hi";
					temperature = <0x69>;
					hysteresis = <0x02>;
				};

				cpu-critical-hi {
					type = "critical_high";
					temperature = <0x7d>;
					hysteresis = <0x02>;
				};

				cpu-critical-low {
					type = "critical_low";
					temperature = <0x00>;
					hysteresis = <0x02>;
				};
			};
		};

		tsens_tz_sensor12 {
			polling-delay-passive = <0x00>;
			thermal-sensors = <0x5f 0x0c>;
			polling-delay = <0x00>;

			trips {

				cpu-config-lo {
					type = "configurable_lo";
					temperature = <0x5f>;
					hysteresis = <0x02>;
				};

				cpu-config-hi {
					type = "configurable_hi";
					temperature = <0x69>;
					hysteresis = <0x02>;
				};

				cpu-critical-hi {
					type = "critical_high";
					temperature = <0x7d>;
					hysteresis = <0x02>;
				};

				cpu-critical-low {
					type = "critical_low";
					temperature = <0x00>;
					hysteresis = <0x02>;
				};
			};
		};

		tsens_tz_sensor9 {
			polling-delay-passive = <0x00>;
			thermal-sensors = <0x5f 0x09>;
			polling-delay = <0x00>;

			trips {

				cpu-config-lo {
					type = "configurable_lo";
					temperature = <0x5f>;
					hysteresis = <0x02>;
				};

				cpu-config-hi {
					type = "configurable_hi";
					temperature = <0x69>;
					hysteresis = <0x02>;
				};

				cpu-critical-hi {
					type = "critical_high";
					temperature = <0x7d>;
					hysteresis = <0x02>;
				};

				cpu-critical-low {
					type = "critical_low";
					temperature = <0x00>;
					hysteresis = <0x02>;
				};
			};
		};

		tsens_tz_sensor15 {
			polling-delay-passive = <0x00>;
			thermal-sensors = <0x5f 0x0f>;
			polling-delay = <0x00>;

			trips {

				cpu-config-lo {
					type = "configurable_lo";
					temperature = <0x5f>;
					hysteresis = <0x02>;
				};

				cpu-config-hi {
					type = "configurable_hi";
					temperature = <0x69>;
					hysteresis = <0x02>;
				};

				cpu-critical-hi {
					type = "critical_high";
					temperature = <0x7d>;
					hysteresis = <0x02>;
				};

				cpu-critical-low {
					type = "critical_low";
					temperature = <0x00>;
					hysteresis = <0x02>;
				};
			};
		};

		tsens_tz_sensor5 {
			polling-delay-passive = <0x00>;
			thermal-sensors = <0x5f 0x05>;
			polling-delay = <0x00>;

			trips {

				cpu-config-lo {
					type = "configurable_lo";
					temperature = <0x5f>;
					hysteresis = <0x02>;
				};

				cpu-config-hi {
					type = "configurable_hi";
					temperature = <0x69>;
					hysteresis = <0x02>;
				};

				cpu-critical-hi {
					type = "critical_high";
					temperature = <0x7d>;
					hysteresis = <0x02>;
				};

				cpu-critical-low {
					type = "critical_low";
					temperature = <0x00>;
					hysteresis = <0x02>;
				};
			};
		};

		tsens_tz_sensor10 {
			polling-delay-passive = <0x00>;
			thermal-sensors = <0x5f 0x0a>;
			polling-delay = <0x00>;

			trips {

				cpu-config-lo {
					type = "configurable_lo";
					temperature = <0x5f>;
					hysteresis = <0x02>;
				};

				cpu-config-hi {
					type = "configurable_hi";
					temperature = <0x69>;
					hysteresis = <0x02>;
				};

				cpu-critical-hi {
					type = "critical_high";
					temperature = <0x7d>;
					hysteresis = <0x02>;
				};

				cpu-critical-low {
					type = "critical_low";
					temperature = <0x00>;
					hysteresis = <0x02>;
				};
			};
		};

		tsens_tz_sensor7 {
			polling-delay-passive = <0x00>;
			thermal-sensors = <0x5f 0x07>;
			polling-delay = <0x00>;

			trips {

				cpu-config-lo {
					type = "configurable_lo";
					temperature = <0x5f>;
					hysteresis = <0x02>;
				};

				cpu-config-hi {
					type = "configurable_hi";
					temperature = <0x69>;
					hysteresis = <0x02>;
				};

				cpu-critical-hi {
					type = "critical_high";
					temperature = <0x7d>;
					hysteresis = <0x02>;
				};

				cpu-critical-low {
					type = "critical_low";
					temperature = <0x00>;
					hysteresis = <0x02>;
				};
			};
		};

		tsens_tz_sensor11 {
			polling-delay-passive = <0x00>;
			thermal-sensors = <0x5f 0x0b>;
			polling-delay = <0x00>;

			trips {

				cpu-config-lo {
					type = "configurable_lo";
					temperature = <0x5f>;
					hysteresis = <0x02>;
				};

				cpu-config-hi {
					type = "configurable_hi";
					temperature = <0x69>;
					hysteresis = <0x02>;
				};

				cpu-critical-hi {
					type = "critical_high";
					temperature = <0x7d>;
					hysteresis = <0x02>;
				};

				cpu-critical-low {
					type = "critical_low";
					temperature = <0x00>;
					hysteresis = <0x02>;
				};
			};
		};
	};

	chosen {
		bootargs-append = " swiotlb=1 coherent_pool=2M";
		bootargs = "console=ttyMSM0,115200n8 root=PARTUUID=b68d7f34-87c4-9787-95e5-72fdcaaf3105 rootwait";
	};

	fixed-regulator@0 {
		regulator-always-on;
		phandle = <0x32>;
		regulator-boot-on;
		regulator-min-microvolt = <0x325aa0>;
		regulator-name = "e-smps1-reg";
		compatible = "regulator-fixed";
		regulator-max-microvolt = <0x325aa0>;
		linux,phandle = <0x32>;
	};

	firmware {

		scm {
			compatible = "qcom,scm-ipq807x";
		};

		qfprom_sec {
			img-addr = "J@\0";
			img-size = <0x700000>;
			compatible = "qcom,qfprom-sec";
		};
	};
};
